AUTOSAR XML (schema 00044)
package /E40_Platform_System_SystemPackage/Components
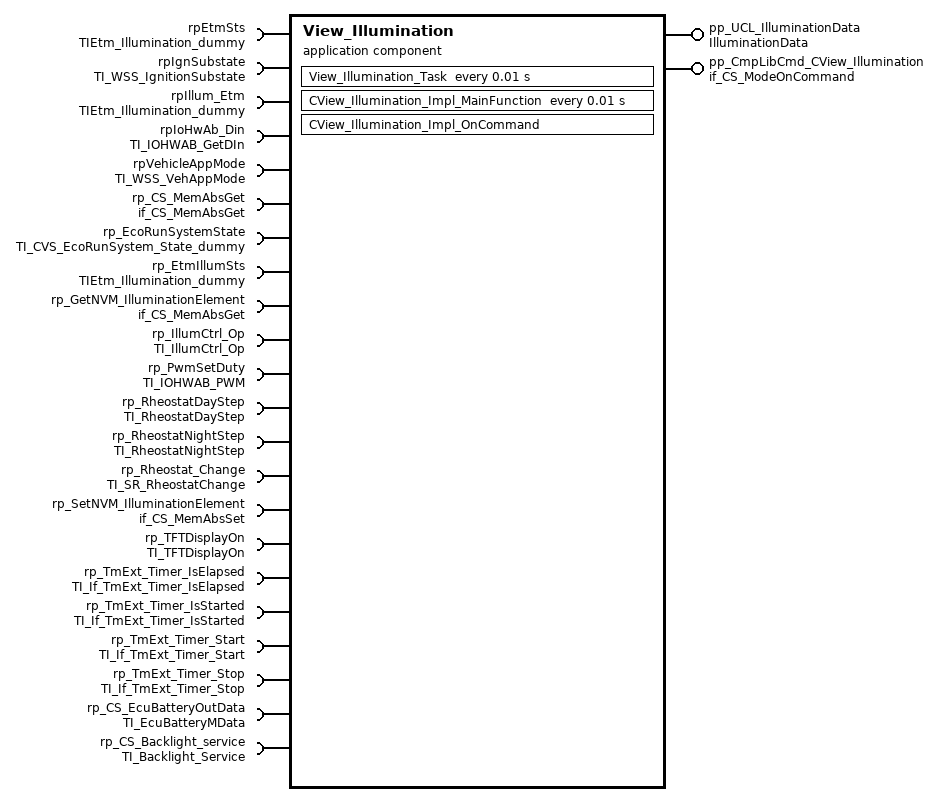
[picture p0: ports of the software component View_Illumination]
  application sw component type View_Illumination
    provide port pp_UCL_IlluminationData: nonqueued-sender-com-spec{data-element=IlluminationDataData, init-value=constant-reference=View_IlluminationIlluminationDataDataValue0}, provided-interface=IlluminationData
    20 x require port:
      rpEtmSts: nonqueued-receiver-com-spec{data-element=IllumStatus, init-value=constant-reference=View_IlluminationIllumStatusValue0}, required-interface=TIEtm_Illumination_dummy
      rpIgnSubstate: nonqueued-receiver-com-spec{data-element=IgnitionSubstate, init-value=constant-reference=View_IlluminationIgnitionSubstateValue0}, required-interface=TI_WSS_IgnitionSubstate
      rpIllum_Etm: nonqueued-receiver-com-spec{data-element=IllumStatus, init-value=constant-reference=View_IlluminationIllumStatusValue0}, required-interface=TIEtm_Illumination_dummy
      rpIoHwAb_Din: required-com-specs=[GetAsyncRawInput, GetInputGroup, GetProcessedInput, GetSyncRawInput], required-interface=TI_IOHWAB_GetDIn
      rpVehicleAppMode: nonqueued-receiver-com-spec{data-element=WSSCurrentVehicleState, init-value=constant-reference=View_IlluminationWSSCurrentVehicleStateValue0}, required-interface=TI_WSS_VehAppMode
      rp_CS_MemAbsGet: required-com-specs=[Get_BsConst_Audio_Element, Get_BsConst_Communication_Element, Get_BsConst_EngOffTimer_Element, Get_BsConst_FuelGauge_Element, Get_BsConst_OilGauge_Element, Get_BsConst_PowerGauge_Element, Get_BsConst_Power_Element, Get_BsConst_RealTimeClock_Element, Get_BsConst_ServiceReminder_Element, Get_BsConst_SpeedoGauge_Element, Get_BsConst_TachoGauge_Element, Get_BsConst_TempGauge_Element, Get_BsConst_TripComputer_Element, Get_BsConst_Warning_Element, Get_BsCys_Certicificate_Element, Get_BsDiag_Dtc_Element, Get_BsDiag_ErrorRecord_Element, Get_BsReten_Audio_Element, Get_BsReten_Communication_Element, Get_BsReten_Display_Element, Get_BsReten_Gauges_Element, Get_BsReten_Illumination_Element, Get_BsReten_Odometer_Element, Get_BsReten_Personalization_Element, Get_BsReten_Power_Element, Get_BsReten_RealTimeClock_Element, Get_BsReten_Tripcomputer_Element, Get_BsReten_Warning_Element, Get_BsRt_CusDlt_Element, Get_BsRt_FuelGauge_Element, Get_BsRt_Illumination_Element, Get_BsRt_Odometer_Element, Get_BsRt_OilGauge_Element, Get_BsRt_Personalization_Element, Get_BsRt_PowerGauge_Element, Get_BsRt_RealTimeClock_Element, Get_BsRt_SpeedoGauge_Element, Get_BsRt_TachoGauge_Element, Get_BsRt_TempGauge_Element, Get_BsRt_TripComputer_Element, Get_BsRt_Warning_Element, Get_BsShare_EcuPartNumber_Element, Get_BsShare_SwUpdFotaFinPrint_Element, Get_BsShare_SwUpdFotaMode_Element, Get_BsShare_SwUpdFotaStatus_Element, Get_BsShare_SwUpdFotadecrypt_Element, Get_BsShare_SwUpdReflash_Element, Get_BsShare_VehicleConfig_Element, Get_BsShare_VisMeet_Element, Get_RefCys_Certicificate1_Element, Get_RefCys_Certicificate_Element, Get_BsShare_VisMeet_EOLEntry_Element, Get_BsShare_AssemblyManufacturingDate, Get_BsShare_AssemblyPlantNumber, Get_BsShare_HWModification, Get_BsShare_PCBSerialNumber, Get_BsShare_ProductSerialNumber, Get_BsShare_SMTManufacturingDate, Get_BsShare_SMTPlantNumber, Get_BsShare_VisteonPCBPartNumber, Get_BsShare_VisteonPartNumber, Get_BsConst_BsConst_Illumination_ReservedByte, Get_BsConst_BsConst_Illumination_ReservedByte_SafeCopy1, Get_BsConst_BsConst_Illumination_ReservedByte_SafeCopy2, Get_BsConst_Compensation_Line_Shift_b, Get_BsConst_Compensation_Line_Shift_b_SafeCopy1, Get_BsConst_Compensation_Line_Shift_b_SafeCopy2, Get_BsConst_Compensation_Line_Slope_m, Get_BsConst_Compensation_Line_Slope_m_SafeCopy1, Get_BsConst_Compensation_Line_Slope_m_SafeCopy2, Get_BsConst_Derating_Backlight_Disable, Get_BsConst_Derating_Backlight_Disable_SafeCopy1, Get_BsConst_Derating_Backlight_Disable_SafeCopy2, Get_BsConst_Display_Illum_Max_Level, Get_BsConst_Display_Illum_Max_Level_SafeCopy1, Get_BsConst_Display_Illum_Max_Level_SafeCopy2, Get_BsConst_Lookup_Curve_HotSpot_Coef_X, Get_BsConst_Lookup_Curve_HotSpot_Coef_X_SafeCopy1, Get_BsConst_Lookup_Curve_HotSpot_Coef_X_SafeCopy2, Get_BsConst_Lookup_Curve_HotSpot_Coef_Y, Get_BsConst_Lookup_Curve_HotSpot_Coef_Y_SafeCopy1, Get_BsConst_Lookup_Curve_HotSpot_Coef_Y_SafeCopy2, Get_BsConst_PCB_Temperature_Sensor_Conv, Get_BsConst_PCB_Temperature_Sensor_Conv_SafeCopy1, Get_BsConst_PCB_Temperature_Sensor_Conv_SafeCopy2, Get_BsConst_PWM_boost_bypass_duty, Get_BsConst_PWM_boost_bypass_duty_SafeCopy1, Get_BsConst_PWM_boost_bypass_duty_SafeCopy2, Get_BsConst_Temp_Threshold_Hysteresis_Derating, Get_BsConst_Temp_Threshold_Hysteresis_Derating_SafeCopy1, Get_BsConst_Temp_Threshold_Hysteresis_Derating_SafeCopy2, Get_BsConst_Temperature_Sensor_Conv, Get_BsConst_Temperature_Sensor_Conv_SafeCopy1, Get_BsConst_Temperature_Sensor_Conv_SafeCopy2], required-interface=if_CS_MemAbsGet
      rp_EcoRunSystemState: nonqueued-receiver-com-spec{data-element=EcoRunSystem_Flag, init-value=constant-reference=View_IlluminationEcoRunSystem_FlagValue0}, required-interface=TI_CVS_EcoRunSystem_State_dummy
      rp_EtmIllumSts: nonqueued-receiver-com-spec{data-element=IllumStatus, init-value=constant-reference=View_IlluminationIllumStatusValue0}, required-interface=TIEtm_Illumination_dummy
      rp_GetNVM_IlluminationElement: required-com-specs=[Get_BsConst_Audio_Element, Get_BsConst_Communication_Element, Get_BsConst_EngOffTimer_Element, Get_BsConst_FuelGauge_Element, Get_BsConst_OilGauge_Element, Get_BsConst_PowerGauge_Element, Get_BsConst_Power_Element, Get_BsConst_RealTimeClock_Element, Get_BsConst_ServiceReminder_Element, Get_BsConst_SpeedoGauge_Element, Get_BsConst_TachoGauge_Element, Get_BsConst_TempGauge_Element, Get_BsConst_TripComputer_Element, Get_BsConst_Warning_Element, Get_BsCys_Certicificate_Element, Get_BsDiag_Dtc_Element, Get_BsDiag_ErrorRecord_Element, Get_BsReten_Audio_Element, Get_BsReten_Communication_Element, Get_BsReten_Display_Element, Get_BsReten_Gauges_Element, Get_BsReten_Illumination_Element, Get_BsReten_Odometer_Element, Get_BsReten_Personalization_Element, Get_BsReten_Power_Element, Get_BsReten_RealTimeClock_Element, Get_BsReten_Tripcomputer_Element, Get_BsReten_Warning_Element, Get_BsRt_CusDlt_Element, Get_BsRt_FuelGauge_Element, Get_BsRt_Illumination_Element, Get_BsRt_Odometer_Element, Get_BsRt_OilGauge_Element, Get_BsRt_Personalization_Element, Get_BsRt_PowerGauge_Element, Get_BsRt_RealTimeClock_Element, Get_BsRt_SpeedoGauge_Element, Get_BsRt_TachoGauge_Element, Get_BsRt_TempGauge_Element, Get_BsRt_TripComputer_Element, Get_BsRt_Warning_Element, Get_BsShare_EcuPartNumber_Element, Get_BsShare_SwUpdFotaFinPrint_Element, Get_BsShare_SwUpdFotaMode_Element, Get_BsShare_SwUpdFotaStatus_Element, Get_BsShare_SwUpdFotadecrypt_Element, Get_BsShare_SwUpdReflash_Element, Get_BsShare_VehicleConfig_Element, Get_BsShare_VisMeet_Element, Get_RefCys_Certicificate1_Element, Get_RefCys_Certicificate_Element, Get_BsShare_VisMeet_EOLEntry_Element, Get_BsShare_AssemblyManufacturingDate, Get_BsShare_AssemblyPlantNumber, Get_BsShare_HWModification, Get_BsShare_PCBSerialNumber, Get_BsShare_ProductSerialNumber, Get_BsShare_SMTManufacturingDate, Get_BsShare_SMTPlantNumber, Get_BsShare_VisteonPCBPartNumber, Get_BsShare_VisteonPartNumber, Get_BsConst_BsConst_Illumination_ReservedByte, Get_BsConst_BsConst_Illumination_ReservedByte_SafeCopy1, Get_BsConst_BsConst_Illumination_ReservedByte_SafeCopy2, Get_BsConst_Compensation_Line_Shift_b, Get_BsConst_Compensation_Line_Shift_b_SafeCopy1, Get_BsConst_Compensation_Line_Shift_b_SafeCopy2, Get_BsConst_Compensation_Line_Slope_m, Get_BsConst_Compensation_Line_Slope_m_SafeCopy1, Get_BsConst_Compensation_Line_Slope_m_SafeCopy2, Get_BsConst_Derating_Backlight_Disable, Get_BsConst_Derating_Backlight_Disable_SafeCopy1, Get_BsConst_Derating_Backlight_Disable_SafeCopy2, Get_BsConst_Display_Illum_Max_Level, Get_BsConst_Display_Illum_Max_Level_SafeCopy1, Get_BsConst_Display_Illum_Max_Level_SafeCopy2, Get_BsConst_Lookup_Curve_HotSpot_Coef_X, Get_BsConst_Lookup_Curve_HotSpot_Coef_X_SafeCopy1, Get_BsConst_Lookup_Curve_HotSpot_Coef_X_SafeCopy2, Get_BsConst_Lookup_Curve_HotSpot_Coef_Y, Get_BsConst_Lookup_Curve_HotSpot_Coef_Y_SafeCopy1, Get_BsConst_Lookup_Curve_HotSpot_Coef_Y_SafeCopy2, Get_BsConst_PCB_Temperature_Sensor_Conv, Get_BsConst_PCB_Temperature_Sensor_Conv_SafeCopy1, Get_BsConst_PCB_Temperature_Sensor_Conv_SafeCopy2, Get_BsConst_PWM_boost_bypass_duty, Get_BsConst_PWM_boost_bypass_duty_SafeCopy1, Get_BsConst_PWM_boost_bypass_duty_SafeCopy2, Get_BsConst_Temp_Threshold_Hysteresis_Derating, Get_BsConst_Temp_Threshold_Hysteresis_Derating_SafeCopy1, Get_BsConst_Temp_Threshold_Hysteresis_Derating_SafeCopy2, Get_BsConst_Temperature_Sensor_Conv, Get_BsConst_Temperature_Sensor_Conv_SafeCopy1, Get_BsConst_Temperature_Sensor_Conv_SafeCopy2], required-interface=if_CS_MemAbsGet
      rp_IllumCtrl_Op: nonqueued-receiver-com-spec{data-element=IllumCtrl_Op_Data, init-value=constant-reference=View_IlluminationIllumCtrl_Op_DataValue0}, required-interface=TI_IllumCtrl_Op
      rp_PwmSetDuty: required-com-specs=[PwmSetDuty, PwmSetDutyAndPeriod, PwmSetIdeal], required-interface=TI_IOHWAB_PWM
      rp_RheostatDayStep: nonqueued-receiver-com-spec{data-element=RheostatDayStep, init-value=constant-reference=View_IlluminationRheostatDayStepValue0}, required-interface=TI_RheostatDayStep
      rp_RheostatNightStep: nonqueued-receiver-com-spec{data-element=RheostatNightStep, init-value=constant-reference=View_IlluminationRheostatNightStepValue0}, required-interface=TI_RheostatNightStep
      rp_Rheostat_Change: nonqueued-receiver-com-spec{data-element=RheoUpdateVal, init-value=constant-reference=View_IlluminationRheoUpdateValValue0}, required-interface=TI_SR_RheostatChange
      rp_SetNVM_IlluminationElement: required-com-specs=[Set_BsConst_Audio_Element, Set_BsConst_Communication_Element, Set_BsConst_EngOffTimer_Element, Set_BsConst_FuelGauge_Element, Set_BsConst_OilGauge_Element, Set_BsConst_PowerGauge_Element, Set_BsConst_Power_Element, Set_BsConst_RealTimeClock_Element, Set_BsConst_ServiceReminder_Element, Set_BsConst_SpeedoGauge_Element, Set_BsConst_TachoGauge_Element, Set_BsConst_TempGauge_Element, Set_BsConst_TripComputer_Element, Set_BsConst_Warning_Element, Set_BsCys_Certicificate_Element, Set_BsDiag_Dtc_Element, Set_BsDiag_ErrorRecord_Element, Set_BsReten_Audio_Element, Set_BsReten_Communication_Element, Set_BsReten_Display_Element, Set_BsReten_Gauges_Element, Set_BsReten_Illumination_Element, Set_BsReten_Odometer_Element, Set_BsReten_Personalization_Element, Set_BsReten_Power_Element, Set_BsReten_RealTimeClock_Element, Set_BsReten_Tripcomputer_Element, Set_BsReten_Warning_Element, Set_BsRt_CusDlt_Element, Set_BsRt_FuelGauge_Element, Set_BsRt_Illumination_Element, Set_BsRt_Odometer_Element, Set_BsRt_OilGauge_Element, Set_BsRt_Personalization_Element, Set_BsRt_PowerGauge_Element, Set_BsRt_RealTimeClock_Element, Set_BsRt_SpeedoGauge_Element, Set_BsRt_TachoGauge_Element, Set_BsRt_TempGauge_Element, Set_BsRt_TripComputer_Element, Set_BsRt_Warning_Element, Set_BsShare_EcuPartNumber_Element, Set_BsShare_SwUpdFotaFinPrint_Element, Set_BsShare_SwUpdFotaMode_Element, Set_BsShare_SwUpdFotaStatus_Element, Set_BsShare_SwUpdFotadecrypt_Element, Set_BsShare_SwUpdReflash_Element, Set_BsShare_VehicleConfig_Element, Set_BsShare_VisMeet_Element, Set_RefCys_Certicificate1_Element, Set_RefCys_Certicificate_Element, Set_BsShare_VisMeet_EOLEntry_Element, Set_BsShare_AssemblyManufacturingDate, Set_BsShare_AssemblyPlantNumber, Set_BsShare_HWModification, Set_BsShare_PCBSerialNumber, Set_BsShare_ProductSerialNumber, Set_BsShare_SMTManufacturingDate, Set_BsShare_SMTPlantNumber, Set_BsShare_VisteonPCBPartNumber, Set_BsShare_VisteonPartNumber, Set_BsConst_BsConst_Illumination_ReservedByte, Set_BsConst_BsConst_Illumination_ReservedByte_SafeCopy1, Set_BsConst_BsConst_Illumination_ReservedByte_SafeCopy2, Set_BsConst_Compensation_Line_Shift_b, Set_BsConst_Compensation_Line_Shift_b_SafeCopy1, Set_BsConst_Compensation_Line_Shift_b_SafeCopy2, Set_BsConst_Compensation_Line_Slope_m, Set_BsConst_Compensation_Line_Slope_m_SafeCopy1, Set_BsConst_Compensation_Line_Slope_m_SafeCopy2, Set_BsConst_Derating_Backlight_Disable, Set_BsConst_Derating_Backlight_Disable_SafeCopy1, Set_BsConst_Derating_Backlight_Disable_SafeCopy2, Set_BsConst_Display_Illum_Max_Level, Set_BsConst_Display_Illum_Max_Level_SafeCopy1, Set_BsConst_Display_Illum_Max_Level_SafeCopy2, Set_BsConst_Lookup_Curve_HotSpot_Coef_X, Set_BsConst_Lookup_Curve_HotSpot_Coef_X_SafeCopy1, Set_BsConst_Lookup_Curve_HotSpot_Coef_X_SafeCopy2, Set_BsConst_Lookup_Curve_HotSpot_Coef_Y, Set_BsConst_Lookup_Curve_HotSpot_Coef_Y_SafeCopy1, Set_BsConst_Lookup_Curve_HotSpot_Coef_Y_SafeCopy2, Set_BsConst_PCB_Temperature_Sensor_Conv, Set_BsConst_PCB_Temperature_Sensor_Conv_SafeCopy1, Set_BsConst_PCB_Temperature_Sensor_Conv_SafeCopy2, Set_BsConst_PWM_boost_bypass_duty, Set_BsConst_PWM_boost_bypass_duty_SafeCopy1, Set_BsConst_PWM_boost_bypass_duty_SafeCopy2, Set_BsConst_Temp_Threshold_Hysteresis_Derating, Set_BsConst_Temp_Threshold_Hysteresis_Derating_SafeCopy1, Set_BsConst_Temp_Threshold_Hysteresis_Derating_SafeCopy2, Set_BsConst_Temperature_Sensor_Conv, Set_BsConst_Temperature_Sensor_Conv_SafeCopy1, Set_BsConst_Temperature_Sensor_Conv_SafeCopy2], required-interface=if_CS_MemAbsSet
      rp_TFTDisplayOn: nonqueued-receiver-com-spec{data-element=TFTDisplayOn, init-value=constant-reference=View_IlluminationTFTDisplayOnValue0}, required-interface=TI_TFTDisplayOn
      rp_TmExt_Timer_IsElapsed: client-com-spec=Timer_IsElapsed, required-interface=TI_If_TmExt_Timer_IsElapsed
      rp_TmExt_Timer_IsStarted: client-com-spec=Timer_IsStarted, required-interface=TI_If_TmExt_Timer_IsStarted
      rp_TmExt_Timer_Start: client-com-spec=Timer_Start, required-interface=TI_If_TmExt_Timer_Start
      rp_TmExt_Timer_Stop: client-com-spec=Timer_Stop, required-interface=TI_If_TmExt_Timer_Stop
    provide port pp_CmpLibCmd_CView_Illumination: server-com-spec{operation=Impl_OnCommand, queue-length=1}, provided-interface=if_CS_ModeOnCommand
    require port rp_CS_EcuBatteryOutData: required-com-specs=[EcuBatteryM_GetChannelStatus, EcuBatteryM_GetDIOStatus], required-interface=TI_EcuBatteryMData
    require port rp_CS_Backlight_service: required-com-specs=[GetBrightnessValue, GetThermalValue, SetBrightnessValue], required-interface=TI_Backlight_Service
    behavior IB_View_Illumination
      timing event TEView_Illumination_Task: start-on-event=View_Illumination_Task, period=0.01
      timing event TECView_Illumination_Impl_MainFunction: start-on-event=CView_Illumination_Impl_MainFunction, period=0.01
      operation invoked event OIE_pp_CmpLibCmd_CView_Illumination_CView_Illumination_Impl_OnCommandTrigByImpl_OnCommand: start-on-event=CView_Illumination_Impl_OnCommand, operation=pp_CmpLibCmd_CView_Illumination.Impl_OnCommand
      port-api-options:
        enable-take-address=false, indirect-api=false, port=pp_UCL_IlluminationData
        enable-take-address=false, indirect-api=false, port=rpEtmSts
        enable-take-address=false, indirect-api=false, port=rpIgnSubstate
        enable-take-address=false, indirect-api=false, port=rpIllum_Etm
        enable-take-address=false, indirect-api=false, port=rpIoHwAb_Din
        enable-take-address=false, indirect-api=false, port=rpVehicleAppMode
        enable-take-address=false, indirect-api=false, port=rp_CS_MemAbsGet
        enable-take-address=false, indirect-api=false, port=rp_EcoRunSystemState
        enable-take-address=false, indirect-api=false, port=rp_EtmIllumSts
        enable-take-address=false, indirect-api=false, port=rp_GetNVM_IlluminationElement
        enable-take-address=false, indirect-api=false, port=rp_IllumCtrl_Op
        enable-take-address=false, indirect-api=false, port=rp_PwmSetDuty
        enable-take-address=false, indirect-api=false, port=rp_RheostatDayStep
        enable-take-address=false, indirect-api=false, port=rp_RheostatNightStep
        enable-take-address=false, indirect-api=false, port=rp_Rheostat_Change
        enable-take-address=false, indirect-api=false, port=rp_SetNVM_IlluminationElement
        enable-take-address=false, indirect-api=false, port=rp_TFTDisplayOn
        enable-take-address=false, indirect-api=false, port=rp_TmExt_Timer_IsElapsed
        enable-take-address=false, indirect-api=false, port=rp_TmExt_Timer_IsStarted
        enable-take-address=false, indirect-api=false, port=rp_TmExt_Timer_Start
        enable-take-address=false, indirect-api=false, port=rp_TmExt_Timer_Stop
        enable-take-address=false, indirect-api=false, port=pp_CmpLibCmd_CView_Illumination
        enable-take-address=false, indirect-api=false, port=rp_CS_EcuBatteryOutData
        enable-take-address=false, indirect-api=false, port=rp_CS_Backlight_service
      runnable View_Illumination_Task: can-be-invoked-concurrently=true
        data-receive-point-by-arguments:
          11 x access:
            DRA_rpEtmSts_IllumStatus: accessed-variable=rpEtmSts.IllumStatus
            DRA_rpIgnSubstate_IgnitionSubstate: accessed-variable=rpIgnSubstate.IgnitionSubstate
            DRA_rpIllum_Etm_IllumStatus: accessed-variable=rpIllum_Etm.IllumStatus
            DRA_rpVehicleAppMode_WSSCurrentVehicleState: accessed-variable=rpVehicleAppMode.WSSCurrentVehicleState
            DRA_rp_EcoRunSystemState_EcoRunSystem_Flag: accessed-variable=rp_EcoRunSystemState.EcoRunSystem_Flag
            DRA_rp_EtmIllumSts_IllumStatus: accessed-variable=rp_EtmIllumSts.IllumStatus
            DRA_rp_IllumCtrl_Op_IllumCtrl_Op_Data: accessed-variable=rp_IllumCtrl_Op.IllumCtrl_Op_Data
            DRA_rp_RheostatDayStep_RheostatDayStep: accessed-variable=rp_RheostatDayStep.RheostatDayStep
            DRA_rp_RheostatNightStep_RheostatNightStep: accessed-variable=rp_RheostatNightStep.RheostatNightStep
            DRA_rp_Rheostat_Change_RheoUpdateVal: accessed-variable=rp_Rheostat_Change.RheoUpdateVal
            DRA_rp_TFTDisplayOn_TFTDisplayOn: accessed-variable=rp_TFTDisplayOn.TFTDisplayOn
        data-send-points:
          access DWA_pp_UCL_IlluminationData_IlluminationDataData: accessed-variable=pp_UCL_IlluminationData.IlluminationDataData
        298 x sync call:
          OA_rpIoHwAb_Din_GetAsyncRawInput: operation=rpIoHwAb_Din.GetAsyncRawInput
          OA_rpIoHwAb_Din_GetProcessedInput: operation=rpIoHwAb_Din.GetProcessedInput
          OA_rpIoHwAb_Din_GetSyncRawInput: operation=rpIoHwAb_Din.GetSyncRawInput
          OA_rpIoHwAb_Din_GetInputGroup: operation=rpIoHwAb_Din.GetInputGroup
          OA_rp_CS_MemAbsGet_Get_BsShare_SwUpdReflash_Element: operation=rp_CS_MemAbsGet.Get_BsShare_SwUpdReflash_Element
          OA_rp_CS_MemAbsGet_Get_BsShare_SwUpdFotaMode_Element: operation=rp_CS_MemAbsGet.Get_BsShare_SwUpdFotaMode_Element
          OA_rp_CS_MemAbsGet_Get_BsShare_SwUpdFotaFinPrint_Element: operation=rp_CS_MemAbsGet.Get_BsShare_SwUpdFotaFinPrint_Element
          OA_rp_CS_MemAbsGet_Get_BsShare_SwUpdFotaStatus_Element: operation=rp_CS_MemAbsGet.Get_BsShare_SwUpdFotaStatus_Element
          OA_rp_CS_MemAbsGet_Get_BsShare_SwUpdFotadecrypt_Element: operation=rp_CS_MemAbsGet.Get_BsShare_SwUpdFotadecrypt_Element
          OA_rp_CS_MemAbsGet_Get_BsShare_EcuPartNumber_Element: operation=rp_CS_MemAbsGet.Get_BsShare_EcuPartNumber_Element
          OA_rp_CS_MemAbsGet_Get_BsShare_VisteonPartNumber: operation=rp_CS_MemAbsGet.Get_BsShare_VisteonPartNumber
          OA_rp_CS_MemAbsGet_Get_BsShare_VisteonPCBPartNumber: operation=rp_CS_MemAbsGet.Get_BsShare_VisteonPCBPartNumber
          OA_rp_CS_MemAbsGet_Get_BsShare_ProductSerialNumber: operation=rp_CS_MemAbsGet.Get_BsShare_ProductSerialNumber
          OA_rp_CS_MemAbsGet_Get_BsShare_PCBSerialNumber: operation=rp_CS_MemAbsGet.Get_BsShare_PCBSerialNumber
          OA_rp_CS_MemAbsGet_Get_BsShare_SMTManufacturingDate: operation=rp_CS_MemAbsGet.Get_BsShare_SMTManufacturingDate
          OA_rp_CS_MemAbsGet_Get_BsShare_AssemblyManufacturingDate: operation=rp_CS_MemAbsGet.Get_BsShare_AssemblyManufacturingDate
          OA_rp_CS_MemAbsGet_Get_BsShare_SMTPlantNumber: operation=rp_CS_MemAbsGet.Get_BsShare_SMTPlantNumber
          OA_rp_CS_MemAbsGet_Get_BsShare_AssemblyPlantNumber: operation=rp_CS_MemAbsGet.Get_BsShare_AssemblyPlantNumber
          OA_rp_CS_MemAbsGet_Get_BsShare_HWModification: operation=rp_CS_MemAbsGet.Get_BsShare_HWModification
          OA_rp_CS_MemAbsGet_Get_BsShare_VisMeet_Element: operation=rp_CS_MemAbsGet.Get_BsShare_VisMeet_Element
          OA_rp_CS_MemAbsGet_Get_BsShare_VisMeet_EOLEntry_Element: operation=rp_CS_MemAbsGet.Get_BsShare_VisMeet_EOLEntry_Element
          OA_rp_CS_MemAbsGet_Get_BsShare_VehicleConfig_Element: operation=rp_CS_MemAbsGet.Get_BsShare_VehicleConfig_Element
          OA_rp_CS_MemAbsGet_Get_BsConst_SpeedoGauge_Element: operation=rp_CS_MemAbsGet.Get_BsConst_SpeedoGauge_Element
          OA_rp_CS_MemAbsGet_Get_BsConst_TachoGauge_Element: operation=rp_CS_MemAbsGet.Get_BsConst_TachoGauge_Element
          OA_rp_CS_MemAbsGet_Get_BsConst_FuelGauge_Element: operation=rp_CS_MemAbsGet.Get_BsConst_FuelGauge_Element
          OA_rp_CS_MemAbsGet_Get_BsConst_TempGauge_Element: operation=rp_CS_MemAbsGet.Get_BsConst_TempGauge_Element
          OA_rp_CS_MemAbsGet_Get_BsConst_PowerGauge_Element: operation=rp_CS_MemAbsGet.Get_BsConst_PowerGauge_Element
          OA_rp_CS_MemAbsGet_Get_BsConst_OilGauge_Element: operation=rp_CS_MemAbsGet.Get_BsConst_OilGauge_Element
          OA_rp_CS_MemAbsGet_Get_BsConst_TripComputer_Element: operation=rp_CS_MemAbsGet.Get_BsConst_TripComputer_Element
          OA_rp_CS_MemAbsGet_Get_BsConst_Compensation_Line_Slope_m: operation=rp_CS_MemAbsGet.Get_BsConst_Compensation_Line_Slope_m
          OA_rp_CS_MemAbsGet_Get_BsConst_Compensation_Line_Shift_b: operation=rp_CS_MemAbsGet.Get_BsConst_Compensation_Line_Shift_b
          OA_rp_CS_MemAbsGet_Get_BsConst_Lookup_Curve_HotSpot_Coef_X: operation=rp_CS_MemAbsGet.Get_BsConst_Lookup_Curve_HotSpot_Coef_X
          OA_rp_CS_MemAbsGet_Get_BsConst_Lookup_Curve_HotSpot_Coef_Y: operation=rp_CS_MemAbsGet.Get_BsConst_Lookup_Curve_HotSpot_Coef_Y
          OA_rp_CS_MemAbsGet_Get_BsConst_Temp_Threshold_Hysteresis_Derating: operation=rp_CS_MemAbsGet.Get_BsConst_Temp_Threshold_Hysteresis_Derating
          OA_rp_CS_MemAbsGet_Get_BsConst_Derating_Backlight_Disable: operation=rp_CS_MemAbsGet.Get_BsConst_Derating_Backlight_Disable
          OA_rp_CS_MemAbsGet_Get_BsConst_Temperature_Sensor_Conv: operation=rp_CS_MemAbsGet.Get_BsConst_Temperature_Sensor_Conv
          OA_rp_CS_MemAbsGet_Get_BsConst_PCB_Temperature_Sensor_Conv: operation=rp_CS_MemAbsGet.Get_BsConst_PCB_Temperature_Sensor_Conv
          OA_rp_CS_MemAbsGet_Get_BsConst_Display_Illum_Max_Level: operation=rp_CS_MemAbsGet.Get_BsConst_Display_Illum_Max_Level
          OA_rp_CS_MemAbsGet_Get_BsConst_PWM_boost_bypass_duty: operation=rp_CS_MemAbsGet.Get_BsConst_PWM_boost_bypass_duty
          OA_rp_CS_MemAbsGet_Get_BsConst_BsConst_Illumination_ReservedByte: operation=rp_CS_MemAbsGet.Get_BsConst_BsConst_Illumination_ReservedByte
          OA_rp_CS_MemAbsGet_Get_BsConst_Compensation_Line_Slope_m_SafeCopy1: operation=rp_CS_MemAbsGet.Get_BsConst_Compensation_Line_Slope_m_SafeCopy1
          OA_rp_CS_MemAbsGet_Get_BsConst_Compensation_Line_Shift_b_SafeCopy1: operation=rp_CS_MemAbsGet.Get_BsConst_Compensation_Line_Shift_b_SafeCopy1
          OA_rp_CS_MemAbsGet_Get_BsConst_Lookup_Curve_HotSpot_Coef_X_SafeCopy1: operation=rp_CS_MemAbsGet.Get_BsConst_Lookup_Curve_HotSpot_Coef_X_SafeCopy1
          OA_rp_CS_MemAbsGet_Get_BsConst_Lookup_Curve_HotSpot_Coef_Y_SafeCopy1: operation=rp_CS_MemAbsGet.Get_BsConst_Lookup_Curve_HotSpot_Coef_Y_SafeCopy1
          OA_rp_CS_MemAbsGet_Get_BsConst_Temp_Threshold_Hysteresis_Derating_SafeCopy1: operation=rp_CS_MemAbsGet.Get_BsConst_Temp_Threshold_Hysteresis_Derating_SafeCopy1
          OA_rp_CS_MemAbsGet_Get_BsConst_Derating_Backlight_Disable_SafeCopy1: operation=rp_CS_MemAbsGet.Get_BsConst_Derating_Backlight_Disable_SafeCopy1
          OA_rp_CS_MemAbsGet_Get_BsConst_Temperature_Sensor_Conv_SafeCopy1: operation=rp_CS_MemAbsGet.Get_BsConst_Temperature_Sensor_Conv_SafeCopy1
          OA_rp_CS_MemAbsGet_Get_BsConst_PCB_Temperature_Sensor_Conv_SafeCopy1: operation=rp_CS_MemAbsGet.Get_BsConst_PCB_Temperature_Sensor_Conv_SafeCopy1
          OA_rp_CS_MemAbsGet_Get_BsConst_Display_Illum_Max_Level_SafeCopy1: operation=rp_CS_MemAbsGet.Get_BsConst_Display_Illum_Max_Level_SafeCopy1
          OA_rp_CS_MemAbsGet_Get_BsConst_PWM_boost_bypass_duty_SafeCopy1: operation=rp_CS_MemAbsGet.Get_BsConst_PWM_boost_bypass_duty_SafeCopy1
          OA_rp_CS_MemAbsGet_Get_BsConst_BsConst_Illumination_ReservedByte_SafeCopy1: operation=rp_CS_MemAbsGet.Get_BsConst_BsConst_Illumination_ReservedByte_SafeCopy1
          OA_rp_CS_MemAbsGet_Get_BsConst_Compensation_Line_Slope_m_SafeCopy2: operation=rp_CS_MemAbsGet.Get_BsConst_Compensation_Line_Slope_m_SafeCopy2
          OA_rp_CS_MemAbsGet_Get_BsConst_Compensation_Line_Shift_b_SafeCopy2: operation=rp_CS_MemAbsGet.Get_BsConst_Compensation_Line_Shift_b_SafeCopy2
          OA_rp_CS_MemAbsGet_Get_BsConst_Lookup_Curve_HotSpot_Coef_X_SafeCopy2: operation=rp_CS_MemAbsGet.Get_BsConst_Lookup_Curve_HotSpot_Coef_X_SafeCopy2
          OA_rp_CS_MemAbsGet_Get_BsConst_Lookup_Curve_HotSpot_Coef_Y_SafeCopy2: operation=rp_CS_MemAbsGet.Get_BsConst_Lookup_Curve_HotSpot_Coef_Y_SafeCopy2
          OA_rp_CS_MemAbsGet_Get_BsConst_Temp_Threshold_Hysteresis_Derating_SafeCopy2: operation=rp_CS_MemAbsGet.Get_BsConst_Temp_Threshold_Hysteresis_Derating_SafeCopy2
          OA_rp_CS_MemAbsGet_Get_BsConst_Derating_Backlight_Disable_SafeCopy2: operation=rp_CS_MemAbsGet.Get_BsConst_Derating_Backlight_Disable_SafeCopy2
          OA_rp_CS_MemAbsGet_Get_BsConst_Temperature_Sensor_Conv_SafeCopy2: operation=rp_CS_MemAbsGet.Get_BsConst_Temperature_Sensor_Conv_SafeCopy2
          OA_rp_CS_MemAbsGet_Get_BsConst_PCB_Temperature_Sensor_Conv_SafeCopy2: operation=rp_CS_MemAbsGet.Get_BsConst_PCB_Temperature_Sensor_Conv_SafeCopy2
          OA_rp_CS_MemAbsGet_Get_BsConst_Display_Illum_Max_Level_SafeCopy2: operation=rp_CS_MemAbsGet.Get_BsConst_Display_Illum_Max_Level_SafeCopy2
          OA_rp_CS_MemAbsGet_Get_BsConst_PWM_boost_bypass_duty_SafeCopy2: operation=rp_CS_MemAbsGet.Get_BsConst_PWM_boost_bypass_duty_SafeCopy2
          OA_rp_CS_MemAbsGet_Get_BsConst_BsConst_Illumination_ReservedByte_SafeCopy2: operation=rp_CS_MemAbsGet.Get_BsConst_BsConst_Illumination_ReservedByte_SafeCopy2
          OA_rp_CS_MemAbsGet_Get_BsConst_Audio_Element: operation=rp_CS_MemAbsGet.Get_BsConst_Audio_Element
          OA_rp_CS_MemAbsGet_Get_BsConst_Warning_Element: operation=rp_CS_MemAbsGet.Get_BsConst_Warning_Element
          OA_rp_CS_MemAbsGet_Get_BsConst_RealTimeClock_Element: operation=rp_CS_MemAbsGet.Get_BsConst_RealTimeClock_Element
          OA_rp_CS_MemAbsGet_Get_BsConst_Communication_Element: operation=rp_CS_MemAbsGet.Get_BsConst_Communication_Element
          OA_rp_CS_MemAbsGet_Get_BsConst_Power_Element: operation=rp_CS_MemAbsGet.Get_BsConst_Power_Element
          OA_rp_CS_MemAbsGet_Get_BsConst_ServiceReminder_Element: operation=rp_CS_MemAbsGet.Get_BsConst_ServiceReminder_Element
          OA_rp_CS_MemAbsGet_Get_BsConst_EngOffTimer_Element: operation=rp_CS_MemAbsGet.Get_BsConst_EngOffTimer_Element
          OA_rp_CS_MemAbsGet_Get_BsCys_Certicificate_Element: operation=rp_CS_MemAbsGet.Get_BsCys_Certicificate_Element
          OA_rp_CS_MemAbsGet_Get_RefCys_Certicificate_Element: operation=rp_CS_MemAbsGet.Get_RefCys_Certicificate_Element
          OA_rp_CS_MemAbsGet_Get_RefCys_Certicificate1_Element: operation=rp_CS_MemAbsGet.Get_RefCys_Certicificate1_Element
          OA_rp_CS_MemAbsGet_Get_BsRt_Odometer_Element: operation=rp_CS_MemAbsGet.Get_BsRt_Odometer_Element
          OA_rp_CS_MemAbsGet_Get_BsRt_SpeedoGauge_Element: operation=rp_CS_MemAbsGet.Get_BsRt_SpeedoGauge_Element
          OA_rp_CS_MemAbsGet_Get_BsRt_TachoGauge_Element: operation=rp_CS_MemAbsGet.Get_BsRt_TachoGauge_Element
          OA_rp_CS_MemAbsGet_Get_BsRt_FuelGauge_Element: operation=rp_CS_MemAbsGet.Get_BsRt_FuelGauge_Element
          OA_rp_CS_MemAbsGet_Get_BsRt_TempGauge_Element: operation=rp_CS_MemAbsGet.Get_BsRt_TempGauge_Element
          OA_rp_CS_MemAbsGet_Get_BsRt_PowerGauge_Element: operation=rp_CS_MemAbsGet.Get_BsRt_PowerGauge_Element
          OA_rp_CS_MemAbsGet_Get_BsRt_OilGauge_Element: operation=rp_CS_MemAbsGet.Get_BsRt_OilGauge_Element
          OA_rp_CS_MemAbsGet_Get_BsRt_TripComputer_Element: operation=rp_CS_MemAbsGet.Get_BsRt_TripComputer_Element
          OA_rp_CS_MemAbsGet_Get_BsRt_Warning_Element: operation=rp_CS_MemAbsGet.Get_BsRt_Warning_Element
          OA_rp_CS_MemAbsGet_Get_BsRt_RealTimeClock_Element: operation=rp_CS_MemAbsGet.Get_BsRt_RealTimeClock_Element
          OA_rp_CS_MemAbsGet_Get_BsRt_Personalization_Element: operation=rp_CS_MemAbsGet.Get_BsRt_Personalization_Element
          OA_rp_CS_MemAbsGet_Get_BsRt_Illumination_Element: operation=rp_CS_MemAbsGet.Get_BsRt_Illumination_Element
          OA_rp_CS_MemAbsGet_Get_BsRt_CusDlt_Element: operation=rp_CS_MemAbsGet.Get_BsRt_CusDlt_Element
          OA_rp_CS_MemAbsGet_Get_BsReten_Odometer_Element: operation=rp_CS_MemAbsGet.Get_BsReten_Odometer_Element
          OA_rp_CS_MemAbsGet_Get_BsReten_Gauges_Element: operation=rp_CS_MemAbsGet.Get_BsReten_Gauges_Element
          OA_rp_CS_MemAbsGet_Get_BsReten_Tripcomputer_Element: operation=rp_CS_MemAbsGet.Get_BsReten_Tripcomputer_Element
          OA_rp_CS_MemAbsGet_Get_BsReten_Illumination_Element: operation=rp_CS_MemAbsGet.Get_BsReten_Illumination_Element
          OA_rp_CS_MemAbsGet_Get_BsReten_Audio_Element: operation=rp_CS_MemAbsGet.Get_BsReten_Audio_Element
          OA_rp_CS_MemAbsGet_Get_BsReten_Warning_Element: operation=rp_CS_MemAbsGet.Get_BsReten_Warning_Element
          OA_rp_CS_MemAbsGet_Get_BsReten_RealTimeClock_Element: operation=rp_CS_MemAbsGet.Get_BsReten_RealTimeClock_Element
          OA_rp_CS_MemAbsGet_Get_BsReten_Communication_Element: operation=rp_CS_MemAbsGet.Get_BsReten_Communication_Element
          OA_rp_CS_MemAbsGet_Get_BsReten_Personalization_Element: operation=rp_CS_MemAbsGet.Get_BsReten_Personalization_Element
          OA_rp_CS_MemAbsGet_Get_BsReten_Power_Element: operation=rp_CS_MemAbsGet.Get_BsReten_Power_Element
          OA_rp_CS_MemAbsGet_Get_BsReten_Display_Element: operation=rp_CS_MemAbsGet.Get_BsReten_Display_Element
          OA_rp_CS_MemAbsGet_Get_BsDiag_ErrorRecord_Element: operation=rp_CS_MemAbsGet.Get_BsDiag_ErrorRecord_Element
          OA_rp_CS_MemAbsGet_Get_BsDiag_Dtc_Element: operation=rp_CS_MemAbsGet.Get_BsDiag_Dtc_Element
          OA_rp_GetNVM_IlluminationElement_Get_BsShare_SwUpdReflash_Element: operation=rp_GetNVM_IlluminationElement.Get_BsShare_SwUpdReflash_Element
          OA_rp_GetNVM_IlluminationElement_Get_BsShare_SwUpdFotaMode_Element: operation=rp_GetNVM_IlluminationElement.Get_BsShare_SwUpdFotaMode_Element
          OA_rp_GetNVM_IlluminationElement_Get_BsShare_SwUpdFotaFinPrint_Element: operation=rp_GetNVM_IlluminationElement.Get_BsShare_SwUpdFotaFinPrint_Element
          OA_rp_GetNVM_IlluminationElement_Get_BsShare_SwUpdFotaStatus_Element: operation=rp_GetNVM_IlluminationElement.Get_BsShare_SwUpdFotaStatus_Element
          OA_rp_GetNVM_IlluminationElement_Get_BsShare_SwUpdFotadecrypt_Element: operation=rp_GetNVM_IlluminationElement.Get_BsShare_SwUpdFotadecrypt_Element
          OA_rp_GetNVM_IlluminationElement_Get_BsShare_EcuPartNumber_Element: operation=rp_GetNVM_IlluminationElement.Get_BsShare_EcuPartNumber_Element
          OA_rp_GetNVM_IlluminationElement_Get_BsShare_VisteonPartNumber: operation=rp_GetNVM_IlluminationElement.Get_BsShare_VisteonPartNumber
          OA_rp_GetNVM_IlluminationElement_Get_BsShare_VisteonPCBPartNumber: operation=rp_GetNVM_IlluminationElement.Get_BsShare_VisteonPCBPartNumber
          OA_rp_GetNVM_IlluminationElement_Get_BsShare_ProductSerialNumber: operation=rp_GetNVM_IlluminationElement.Get_BsShare_ProductSerialNumber
          OA_rp_GetNVM_IlluminationElement_Get_BsShare_PCBSerialNumber: operation=rp_GetNVM_IlluminationElement.Get_BsShare_PCBSerialNumber
          OA_rp_GetNVM_IlluminationElement_Get_BsShare_SMTManufacturingDate: operation=rp_GetNVM_IlluminationElement.Get_BsShare_SMTManufacturingDate
          OA_rp_GetNVM_IlluminationElement_Get_BsShare_AssemblyManufacturingDate: operation=rp_GetNVM_IlluminationElement.Get_BsShare_AssemblyManufacturingDate
          OA_rp_GetNVM_IlluminationElement_Get_BsShare_SMTPlantNumber: operation=rp_GetNVM_IlluminationElement.Get_BsShare_SMTPlantNumber
          OA_rp_GetNVM_IlluminationElement_Get_BsShare_AssemblyPlantNumber: operation=rp_GetNVM_IlluminationElement.Get_BsShare_AssemblyPlantNumber
          OA_rp_GetNVM_IlluminationElement_Get_BsShare_HWModification: operation=rp_GetNVM_IlluminationElement.Get_BsShare_HWModification
          OA_rp_GetNVM_IlluminationElement_Get_BsShare_VisMeet_Element: operation=rp_GetNVM_IlluminationElement.Get_BsShare_VisMeet_Element
          OA_rp_GetNVM_IlluminationElement_Get_BsShare_VisMeet_EOLEntry_Element: operation=rp_GetNVM_IlluminationElement.Get_BsShare_VisMeet_EOLEntry_Element
          OA_rp_GetNVM_IlluminationElement_Get_BsShare_VehicleConfig_Element: operation=rp_GetNVM_IlluminationElement.Get_BsShare_VehicleConfig_Element
          OA_rp_GetNVM_IlluminationElement_Get_BsConst_SpeedoGauge_Element: operation=rp_GetNVM_IlluminationElement.Get_BsConst_SpeedoGauge_Element
          OA_rp_GetNVM_IlluminationElement_Get_BsConst_TachoGauge_Element: operation=rp_GetNVM_IlluminationElement.Get_BsConst_TachoGauge_Element
          OA_rp_GetNVM_IlluminationElement_Get_BsConst_FuelGauge_Element: operation=rp_GetNVM_IlluminationElement.Get_BsConst_FuelGauge_Element
          OA_rp_GetNVM_IlluminationElement_Get_BsConst_TempGauge_Element: operation=rp_GetNVM_IlluminationElement.Get_BsConst_TempGauge_Element
          OA_rp_GetNVM_IlluminationElement_Get_BsConst_PowerGauge_Element: operation=rp_GetNVM_IlluminationElement.Get_BsConst_PowerGauge_Element
          OA_rp_GetNVM_IlluminationElement_Get_BsConst_OilGauge_Element: operation=rp_GetNVM_IlluminationElement.Get_BsConst_OilGauge_Element
          OA_rp_GetNVM_IlluminationElement_Get_BsConst_TripComputer_Element: operation=rp_GetNVM_IlluminationElement.Get_BsConst_TripComputer_Element
          OA_rp_GetNVM_IlluminationElement_Get_BsConst_Compensation_Line_Slope_m: operation=rp_GetNVM_IlluminationElement.Get_BsConst_Compensation_Line_Slope_m
          OA_rp_GetNVM_IlluminationElement_Get_BsConst_Compensation_Line_Shift_b: operation=rp_GetNVM_IlluminationElement.Get_BsConst_Compensation_Line_Shift_b
          OA_rp_GetNVM_IlluminationElement_Get_BsConst_Lookup_Curve_HotSpot_Coef_X: operation=rp_GetNVM_IlluminationElement.Get_BsConst_Lookup_Curve_HotSpot_Coef_X
          OA_rp_GetNVM_IlluminationElement_Get_BsConst_Lookup_Curve_HotSpot_Coef_Y: operation=rp_GetNVM_IlluminationElement.Get_BsConst_Lookup_Curve_HotSpot_Coef_Y
          OA_rp_GetNVM_IlluminationElement_Get_BsConst_Temp_Threshold_Hysteresis_Derating: operation=rp_GetNVM_IlluminationElement.Get_BsConst_Temp_Threshold_Hysteresis_Derating
          OA_rp_GetNVM_IlluminationElement_Get_BsConst_Derating_Backlight_Disable: operation=rp_GetNVM_IlluminationElement.Get_BsConst_Derating_Backlight_Disable
          OA_rp_GetNVM_IlluminationElement_Get_BsConst_Temperature_Sensor_Conv: operation=rp_GetNVM_IlluminationElement.Get_BsConst_Temperature_Sensor_Conv
          OA_rp_GetNVM_IlluminationElement_Get_BsConst_PCB_Temperature_Sensor_Conv: operation=rp_GetNVM_IlluminationElement.Get_BsConst_PCB_Temperature_Sensor_Conv
          OA_rp_GetNVM_IlluminationElement_Get_BsConst_Display_Illum_Max_Level: operation=rp_GetNVM_IlluminationElement.Get_BsConst_Display_Illum_Max_Level
          OA_rp_GetNVM_IlluminationElement_Get_BsConst_PWM_boost_bypass_duty: operation=rp_GetNVM_IlluminationElement.Get_BsConst_PWM_boost_bypass_duty
          OA_rp_GetNVM_IlluminationElement_Get_BsConst_BsConst_Illumination_ReservedByte: operation=rp_GetNVM_IlluminationElement.Get_BsConst_BsConst_Illumination_ReservedByte
          OA_rp_GetNVM_IlluminationElement_Get_BsConst_Compensation_Line_Slope_m_SafeCopy1: operation=rp_GetNVM_IlluminationElement.Get_BsConst_Compensation_Line_Slope_m_SafeCopy1
          OA_rp_GetNVM_IlluminationElement_Get_BsConst_Compensation_Line_Shift_b_SafeCopy1: operation=rp_GetNVM_IlluminationElement.Get_BsConst_Compensation_Line_Shift_b_SafeCopy1
          OA_rp_GetNVM_IlluminationElement_Get_BsConst_Lookup_Curve_HotSpot_Coef_X_SafeCopy1: operation=rp_GetNVM_IlluminationElement.Get_BsConst_Lookup_Curve_HotSpot_Coef_X_SafeCopy1
          OA_rp_GetNVM_IlluminationElement_Get_BsConst_Lookup_Curve_HotSpot_Coef_Y_SafeCopy1: operation=rp_GetNVM_IlluminationElement.Get_BsConst_Lookup_Curve_HotSpot_Coef_Y_SafeCopy1
          OA_rp_GetNVM_IlluminationElement_Get_BsConst_Temp_Threshold_Hysteresis_Derating_SafeCopy1: operation=rp_GetNVM_IlluminationElement.Get_BsConst_Temp_Threshold_Hysteresis_Derating_SafeCopy1
          OA_rp_GetNVM_IlluminationElement_Get_BsConst_Derating_Backlight_Disable_SafeCopy1: operation=rp_GetNVM_IlluminationElement.Get_BsConst_Derating_Backlight_Disable_SafeCopy1
          OA_rp_GetNVM_IlluminationElement_Get_BsConst_Temperature_Sensor_Conv_SafeCopy1: operation=rp_GetNVM_IlluminationElement.Get_BsConst_Temperature_Sensor_Conv_SafeCopy1
          OA_rp_GetNVM_IlluminationElement_Get_BsConst_PCB_Temperature_Sensor_Conv_SafeCopy1: operation=rp_GetNVM_IlluminationElement.Get_BsConst_PCB_Temperature_Sensor_Conv_SafeCopy1
          OA_rp_GetNVM_IlluminationElement_Get_BsConst_Display_Illum_Max_Level_SafeCopy1: operation=rp_GetNVM_IlluminationElement.Get_BsConst_Display_Illum_Max_Level_SafeCopy1
          OA_rp_GetNVM_IlluminationElement_Get_BsConst_PWM_boost_bypass_duty_SafeCopy1: operation=rp_GetNVM_IlluminationElement.Get_BsConst_PWM_boost_bypass_duty_SafeCopy1
          OA_rp_GetNVM_IlluminationElement_Get_BsConst_BsConst_Illumination_ReservedByte_SafeCopy1: operation=rp_GetNVM_IlluminationElement.Get_BsConst_BsConst_Illumination_ReservedByte_SafeCopy1
          OA_rp_GetNVM_IlluminationElement_Get_BsConst_Compensation_Line_Slope_m_SafeCopy2: operation=rp_GetNVM_IlluminationElement.Get_BsConst_Compensation_Line_Slope_m_SafeCopy2
          OA_rp_GetNVM_IlluminationElement_Get_BsConst_Compensation_Line_Shift_b_SafeCopy2: operation=rp_GetNVM_IlluminationElement.Get_BsConst_Compensation_Line_Shift_b_SafeCopy2
          OA_rp_GetNVM_IlluminationElement_Get_BsConst_Lookup_Curve_HotSpot_Coef_X_SafeCopy2: operation=rp_GetNVM_IlluminationElement.Get_BsConst_Lookup_Curve_HotSpot_Coef_X_SafeCopy2
          OA_rp_GetNVM_IlluminationElement_Get_BsConst_Lookup_Curve_HotSpot_Coef_Y_SafeCopy2: operation=rp_GetNVM_IlluminationElement.Get_BsConst_Lookup_Curve_HotSpot_Coef_Y_SafeCopy2
          OA_rp_GetNVM_IlluminationElement_Get_BsConst_Temp_Threshold_Hysteresis_Derating_SafeCopy2: operation=rp_GetNVM_IlluminationElement.Get_BsConst_Temp_Threshold_Hysteresis_Derating_SafeCopy2
          OA_rp_GetNVM_IlluminationElement_Get_BsConst_Derating_Backlight_Disable_SafeCopy2: operation=rp_GetNVM_IlluminationElement.Get_BsConst_Derating_Backlight_Disable_SafeCopy2
          OA_rp_GetNVM_IlluminationElement_Get_BsConst_Temperature_Sensor_Conv_SafeCopy2: operation=rp_GetNVM_IlluminationElement.Get_BsConst_Temperature_Sensor_Conv_SafeCopy2
          OA_rp_GetNVM_IlluminationElement_Get_BsConst_PCB_Temperature_Sensor_Conv_SafeCopy2: operation=rp_GetNVM_IlluminationElement.Get_BsConst_PCB_Temperature_Sensor_Conv_SafeCopy2
          OA_rp_GetNVM_IlluminationElement_Get_BsConst_Display_Illum_Max_Level_SafeCopy2: operation=rp_GetNVM_IlluminationElement.Get_BsConst_Display_Illum_Max_Level_SafeCopy2
          OA_rp_GetNVM_IlluminationElement_Get_BsConst_PWM_boost_bypass_duty_SafeCopy2: operation=rp_GetNVM_IlluminationElement.Get_BsConst_PWM_boost_bypass_duty_SafeCopy2
          OA_rp_GetNVM_IlluminationElement_Get_BsConst_BsConst_Illumination_ReservedByte_SafeCopy2: operation=rp_GetNVM_IlluminationElement.Get_BsConst_BsConst_Illumination_ReservedByte_SafeCopy2
          OA_rp_GetNVM_IlluminationElement_Get_BsConst_Audio_Element: operation=rp_GetNVM_IlluminationElement.Get_BsConst_Audio_Element
          OA_rp_GetNVM_IlluminationElement_Get_BsConst_Warning_Element: operation=rp_GetNVM_IlluminationElement.Get_BsConst_Warning_Element
          OA_rp_GetNVM_IlluminationElement_Get_BsConst_RealTimeClock_Element: operation=rp_GetNVM_IlluminationElement.Get_BsConst_RealTimeClock_Element
          OA_rp_GetNVM_IlluminationElement_Get_BsConst_Communication_Element: operation=rp_GetNVM_IlluminationElement.Get_BsConst_Communication_Element
          OA_rp_GetNVM_IlluminationElement_Get_BsConst_Power_Element: operation=rp_GetNVM_IlluminationElement.Get_BsConst_Power_Element
          OA_rp_GetNVM_IlluminationElement_Get_BsConst_ServiceReminder_Element: operation=rp_GetNVM_IlluminationElement.Get_BsConst_ServiceReminder_Element
          OA_rp_GetNVM_IlluminationElement_Get_BsConst_EngOffTimer_Element: operation=rp_GetNVM_IlluminationElement.Get_BsConst_EngOffTimer_Element
          OA_rp_GetNVM_IlluminationElement_Get_BsCys_Certicificate_Element: operation=rp_GetNVM_IlluminationElement.Get_BsCys_Certicificate_Element
          OA_rp_GetNVM_IlluminationElement_Get_RefCys_Certicificate_Element: operation=rp_GetNVM_IlluminationElement.Get_RefCys_Certicificate_Element
          OA_rp_GetNVM_IlluminationElement_Get_RefCys_Certicificate1_Element: operation=rp_GetNVM_IlluminationElement.Get_RefCys_Certicificate1_Element
          OA_rp_GetNVM_IlluminationElement_Get_BsRt_Odometer_Element: operation=rp_GetNVM_IlluminationElement.Get_BsRt_Odometer_Element
          OA_rp_GetNVM_IlluminationElement_Get_BsRt_SpeedoGauge_Element: operation=rp_GetNVM_IlluminationElement.Get_BsRt_SpeedoGauge_Element
          OA_rp_GetNVM_IlluminationElement_Get_BsRt_TachoGauge_Element: operation=rp_GetNVM_IlluminationElement.Get_BsRt_TachoGauge_Element
          OA_rp_GetNVM_IlluminationElement_Get_BsRt_FuelGauge_Element: operation=rp_GetNVM_IlluminationElement.Get_BsRt_FuelGauge_Element
          OA_rp_GetNVM_IlluminationElement_Get_BsRt_TempGauge_Element: operation=rp_GetNVM_IlluminationElement.Get_BsRt_TempGauge_Element
          OA_rp_GetNVM_IlluminationElement_Get_BsRt_PowerGauge_Element: operation=rp_GetNVM_IlluminationElement.Get_BsRt_PowerGauge_Element
          OA_rp_GetNVM_IlluminationElement_Get_BsRt_OilGauge_Element: operation=rp_GetNVM_IlluminationElement.Get_BsRt_OilGauge_Element
          OA_rp_GetNVM_IlluminationElement_Get_BsRt_TripComputer_Element: operation=rp_GetNVM_IlluminationElement.Get_BsRt_TripComputer_Element
          OA_rp_GetNVM_IlluminationElement_Get_BsRt_Warning_Element: operation=rp_GetNVM_IlluminationElement.Get_BsRt_Warning_Element
          OA_rp_GetNVM_IlluminationElement_Get_BsRt_RealTimeClock_Element: operation=rp_GetNVM_IlluminationElement.Get_BsRt_RealTimeClock_Element
          OA_rp_GetNVM_IlluminationElement_Get_BsRt_Personalization_Element: operation=rp_GetNVM_IlluminationElement.Get_BsRt_Personalization_Element
          OA_rp_GetNVM_IlluminationElement_Get_BsRt_Illumination_Element: operation=rp_GetNVM_IlluminationElement.Get_BsRt_Illumination_Element
          OA_rp_GetNVM_IlluminationElement_Get_BsRt_CusDlt_Element: operation=rp_GetNVM_IlluminationElement.Get_BsRt_CusDlt_Element
          OA_rp_GetNVM_IlluminationElement_Get_BsReten_Odometer_Element: operation=rp_GetNVM_IlluminationElement.Get_BsReten_Odometer_Element
          OA_rp_GetNVM_IlluminationElement_Get_BsReten_Gauges_Element: operation=rp_GetNVM_IlluminationElement.Get_BsReten_Gauges_Element
          OA_rp_GetNVM_IlluminationElement_Get_BsReten_Tripcomputer_Element: operation=rp_GetNVM_IlluminationElement.Get_BsReten_Tripcomputer_Element
          OA_rp_GetNVM_IlluminationElement_Get_BsReten_Illumination_Element: operation=rp_GetNVM_IlluminationElement.Get_BsReten_Illumination_Element
          OA_rp_GetNVM_IlluminationElement_Get_BsReten_Audio_Element: operation=rp_GetNVM_IlluminationElement.Get_BsReten_Audio_Element
          OA_rp_GetNVM_IlluminationElement_Get_BsReten_Warning_Element: operation=rp_GetNVM_IlluminationElement.Get_BsReten_Warning_Element
          OA_rp_GetNVM_IlluminationElement_Get_BsReten_RealTimeClock_Element: operation=rp_GetNVM_IlluminationElement.Get_BsReten_RealTimeClock_Element
          OA_rp_GetNVM_IlluminationElement_Get_BsReten_Communication_Element: operation=rp_GetNVM_IlluminationElement.Get_BsReten_Communication_Element
          OA_rp_GetNVM_IlluminationElement_Get_BsReten_Personalization_Element: operation=rp_GetNVM_IlluminationElement.Get_BsReten_Personalization_Element
          OA_rp_GetNVM_IlluminationElement_Get_BsReten_Power_Element: operation=rp_GetNVM_IlluminationElement.Get_BsReten_Power_Element
          OA_rp_GetNVM_IlluminationElement_Get_BsReten_Display_Element: operation=rp_GetNVM_IlluminationElement.Get_BsReten_Display_Element
          OA_rp_GetNVM_IlluminationElement_Get_BsDiag_ErrorRecord_Element: operation=rp_GetNVM_IlluminationElement.Get_BsDiag_ErrorRecord_Element
          OA_rp_GetNVM_IlluminationElement_Get_BsDiag_Dtc_Element: operation=rp_GetNVM_IlluminationElement.Get_BsDiag_Dtc_Element
          OA_rp_PwmSetDuty_PwmSetDuty: operation=rp_PwmSetDuty.PwmSetDuty
          OA_rp_PwmSetDuty_PwmSetDutyAndPeriod: operation=rp_PwmSetDuty.PwmSetDutyAndPeriod
          OA_rp_PwmSetDuty_PwmSetIdeal: operation=rp_PwmSetDuty.PwmSetIdeal
          OA_rp_SetNVM_IlluminationElement_Set_BsShare_SwUpdReflash_Element: operation=rp_SetNVM_IlluminationElement.Set_BsShare_SwUpdReflash_Element
          OA_rp_SetNVM_IlluminationElement_Set_BsShare_SwUpdFotaMode_Element: operation=rp_SetNVM_IlluminationElement.Set_BsShare_SwUpdFotaMode_Element
          OA_rp_SetNVM_IlluminationElement_Set_BsShare_SwUpdFotaFinPrint_Element: operation=rp_SetNVM_IlluminationElement.Set_BsShare_SwUpdFotaFinPrint_Element
          OA_rp_SetNVM_IlluminationElement_Set_BsShare_SwUpdFotaStatus_Element: operation=rp_SetNVM_IlluminationElement.Set_BsShare_SwUpdFotaStatus_Element
          OA_rp_SetNVM_IlluminationElement_Set_BsShare_SwUpdFotadecrypt_Element: operation=rp_SetNVM_IlluminationElement.Set_BsShare_SwUpdFotadecrypt_Element
          OA_rp_SetNVM_IlluminationElement_Set_BsShare_EcuPartNumber_Element: operation=rp_SetNVM_IlluminationElement.Set_BsShare_EcuPartNumber_Element
          OA_rp_SetNVM_IlluminationElement_Set_BsShare_VisteonPartNumber: operation=rp_SetNVM_IlluminationElement.Set_BsShare_VisteonPartNumber
          OA_rp_SetNVM_IlluminationElement_Set_BsShare_VisteonPCBPartNumber: operation=rp_SetNVM_IlluminationElement.Set_BsShare_VisteonPCBPartNumber
          OA_rp_SetNVM_IlluminationElement_Set_BsShare_ProductSerialNumber: operation=rp_SetNVM_IlluminationElement.Set_BsShare_ProductSerialNumber
          OA_rp_SetNVM_IlluminationElement_Set_BsShare_PCBSerialNumber: operation=rp_SetNVM_IlluminationElement.Set_BsShare_PCBSerialNumber
          OA_rp_SetNVM_IlluminationElement_Set_BsShare_SMTManufacturingDate: operation=rp_SetNVM_IlluminationElement.Set_BsShare_SMTManufacturingDate
          OA_rp_SetNVM_IlluminationElement_Set_BsShare_AssemblyManufacturingDate: operation=rp_SetNVM_IlluminationElement.Set_BsShare_AssemblyManufacturingDate
          OA_rp_SetNVM_IlluminationElement_Set_BsShare_SMTPlantNumber: operation=rp_SetNVM_IlluminationElement.Set_BsShare_SMTPlantNumber
          OA_rp_SetNVM_IlluminationElement_Set_BsShare_AssemblyPlantNumber: operation=rp_SetNVM_IlluminationElement.Set_BsShare_AssemblyPlantNumber
          OA_rp_SetNVM_IlluminationElement_Set_BsShare_HWModification: operation=rp_SetNVM_IlluminationElement.Set_BsShare_HWModification
          OA_rp_SetNVM_IlluminationElement_Set_BsShare_VisMeet_Element: operation=rp_SetNVM_IlluminationElement.Set_BsShare_VisMeet_Element
          OA_rp_SetNVM_IlluminationElement_Set_BsShare_VisMeet_EOLEntry_Element: operation=rp_SetNVM_IlluminationElement.Set_BsShare_VisMeet_EOLEntry_Element
          OA_rp_SetNVM_IlluminationElement_Set_BsShare_VehicleConfig_Element: operation=rp_SetNVM_IlluminationElement.Set_BsShare_VehicleConfig_Element
          OA_rp_SetNVM_IlluminationElement_Set_BsConst_SpeedoGauge_Element: operation=rp_SetNVM_IlluminationElement.Set_BsConst_SpeedoGauge_Element
          OA_rp_SetNVM_IlluminationElement_Set_BsConst_TachoGauge_Element: operation=rp_SetNVM_IlluminationElement.Set_BsConst_TachoGauge_Element
          OA_rp_SetNVM_IlluminationElement_Set_BsConst_FuelGauge_Element: operation=rp_SetNVM_IlluminationElement.Set_BsConst_FuelGauge_Element
          OA_rp_SetNVM_IlluminationElement_Set_BsConst_TempGauge_Element: operation=rp_SetNVM_IlluminationElement.Set_BsConst_TempGauge_Element
          OA_rp_SetNVM_IlluminationElement_Set_BsConst_PowerGauge_Element: operation=rp_SetNVM_IlluminationElement.Set_BsConst_PowerGauge_Element
          OA_rp_SetNVM_IlluminationElement_Set_BsConst_OilGauge_Element: operation=rp_SetNVM_IlluminationElement.Set_BsConst_OilGauge_Element
          OA_rp_SetNVM_IlluminationElement_Set_BsConst_TripComputer_Element: operation=rp_SetNVM_IlluminationElement.Set_BsConst_TripComputer_Element
          OA_rp_SetNVM_IlluminationElement_Set_BsConst_Compensation_Line_Slope_m: operation=rp_SetNVM_IlluminationElement.Set_BsConst_Compensation_Line_Slope_m
          OA_rp_SetNVM_IlluminationElement_Set_BsConst_Compensation_Line_Shift_b: operation=rp_SetNVM_IlluminationElement.Set_BsConst_Compensation_Line_Shift_b
          OA_rp_SetNVM_IlluminationElement_Set_BsConst_Lookup_Curve_HotSpot_Coef_X: operation=rp_SetNVM_IlluminationElement.Set_BsConst_Lookup_Curve_HotSpot_Coef_X
          OA_rp_SetNVM_IlluminationElement_Set_BsConst_Lookup_Curve_HotSpot_Coef_Y: operation=rp_SetNVM_IlluminationElement.Set_BsConst_Lookup_Curve_HotSpot_Coef_Y
          OA_rp_SetNVM_IlluminationElement_Set_BsConst_Temp_Threshold_Hysteresis_Derating: operation=rp_SetNVM_IlluminationElement.Set_BsConst_Temp_Threshold_Hysteresis_Derating
          OA_rp_SetNVM_IlluminationElement_Set_BsConst_Derating_Backlight_Disable: operation=rp_SetNVM_IlluminationElement.Set_BsConst_Derating_Backlight_Disable
          OA_rp_SetNVM_IlluminationElement_Set_BsConst_Temperature_Sensor_Conv: operation=rp_SetNVM_IlluminationElement.Set_BsConst_Temperature_Sensor_Conv
          OA_rp_SetNVM_IlluminationElement_Set_BsConst_PCB_Temperature_Sensor_Conv: operation=rp_SetNVM_IlluminationElement.Set_BsConst_PCB_Temperature_Sensor_Conv
          OA_rp_SetNVM_IlluminationElement_Set_BsConst_Display_Illum_Max_Level: operation=rp_SetNVM_IlluminationElement.Set_BsConst_Display_Illum_Max_Level
          OA_rp_SetNVM_IlluminationElement_Set_BsConst_PWM_boost_bypass_duty: operation=rp_SetNVM_IlluminationElement.Set_BsConst_PWM_boost_bypass_duty
          OA_rp_SetNVM_IlluminationElement_Set_BsConst_BsConst_Illumination_ReservedByte: operation=rp_SetNVM_IlluminationElement.Set_BsConst_BsConst_Illumination_ReservedByte
          OA_rp_SetNVM_IlluminationElement_Set_BsConst_Compensation_Line_Slope_m_SafeCopy1: operation=rp_SetNVM_IlluminationElement.Set_BsConst_Compensation_Line_Slope_m_SafeCopy1
          OA_rp_SetNVM_IlluminationElement_Set_BsConst_Compensation_Line_Shift_b_SafeCopy1: operation=rp_SetNVM_IlluminationElement.Set_BsConst_Compensation_Line_Shift_b_SafeCopy1
          OA_rp_SetNVM_IlluminationElement_Set_BsConst_Lookup_Curve_HotSpot_Coef_X_SafeCopy1: operation=rp_SetNVM_IlluminationElement.Set_BsConst_Lookup_Curve_HotSpot_Coef_X_SafeCopy1
          OA_rp_SetNVM_IlluminationElement_Set_BsConst_Lookup_Curve_HotSpot_Coef_Y_SafeCopy1: operation=rp_SetNVM_IlluminationElement.Set_BsConst_Lookup_Curve_HotSpot_Coef_Y_SafeCopy1
          OA_rp_SetNVM_IlluminationElement_Set_BsConst_Temp_Threshold_Hysteresis_Derating_SafeCopy1: operation=rp_SetNVM_IlluminationElement.Set_BsConst_Temp_Threshold_Hysteresis_Derating_SafeCopy1
          OA_rp_SetNVM_IlluminationElement_Set_BsConst_Derating_Backlight_Disable_SafeCopy1: operation=rp_SetNVM_IlluminationElement.Set_BsConst_Derating_Backlight_Disable_SafeCopy1
          OA_rp_SetNVM_IlluminationElement_Set_BsConst_Temperature_Sensor_Conv_SafeCopy1: operation=rp_SetNVM_IlluminationElement.Set_BsConst_Temperature_Sensor_Conv_SafeCopy1
          OA_rp_SetNVM_IlluminationElement_Set_BsConst_PCB_Temperature_Sensor_Conv_SafeCopy1: operation=rp_SetNVM_IlluminationElement.Set_BsConst_PCB_Temperature_Sensor_Conv_SafeCopy1
          OA_rp_SetNVM_IlluminationElement_Set_BsConst_Display_Illum_Max_Level_SafeCopy1: operation=rp_SetNVM_IlluminationElement.Set_BsConst_Display_Illum_Max_Level_SafeCopy1
          OA_rp_SetNVM_IlluminationElement_Set_BsConst_PWM_boost_bypass_duty_SafeCopy1: operation=rp_SetNVM_IlluminationElement.Set_BsConst_PWM_boost_bypass_duty_SafeCopy1
          OA_rp_SetNVM_IlluminationElement_Set_BsConst_BsConst_Illumination_ReservedByte_SafeCopy1: operation=rp_SetNVM_IlluminationElement.Set_BsConst_BsConst_Illumination_ReservedByte_SafeCopy1
          OA_rp_SetNVM_IlluminationElement_Set_BsConst_Compensation_Line_Slope_m_SafeCopy2: operation=rp_SetNVM_IlluminationElement.Set_BsConst_Compensation_Line_Slope_m_SafeCopy2
          OA_rp_SetNVM_IlluminationElement_Set_BsConst_Compensation_Line_Shift_b_SafeCopy2: operation=rp_SetNVM_IlluminationElement.Set_BsConst_Compensation_Line_Shift_b_SafeCopy2
          OA_rp_SetNVM_IlluminationElement_Set_BsConst_Lookup_Curve_HotSpot_Coef_X_SafeCopy2: operation=rp_SetNVM_IlluminationElement.Set_BsConst_Lookup_Curve_HotSpot_Coef_X_SafeCopy2
          OA_rp_SetNVM_IlluminationElement_Set_BsConst_Lookup_Curve_HotSpot_Coef_Y_SafeCopy2: operation=rp_SetNVM_IlluminationElement.Set_BsConst_Lookup_Curve_HotSpot_Coef_Y_SafeCopy2
          OA_rp_SetNVM_IlluminationElement_Set_BsConst_Temp_Threshold_Hysteresis_Derating_SafeCopy2: operation=rp_SetNVM_IlluminationElement.Set_BsConst_Temp_Threshold_Hysteresis_Derating_SafeCopy2
          OA_rp_SetNVM_IlluminationElement_Set_BsConst_Derating_Backlight_Disable_SafeCopy2: operation=rp_SetNVM_IlluminationElement.Set_BsConst_Derating_Backlight_Disable_SafeCopy2
          OA_rp_SetNVM_IlluminationElement_Set_BsConst_Temperature_Sensor_Conv_SafeCopy2: operation=rp_SetNVM_IlluminationElement.Set_BsConst_Temperature_Sensor_Conv_SafeCopy2
          OA_rp_SetNVM_IlluminationElement_Set_BsConst_PCB_Temperature_Sensor_Conv_SafeCopy2: operation=rp_SetNVM_IlluminationElement.Set_BsConst_PCB_Temperature_Sensor_Conv_SafeCopy2
          OA_rp_SetNVM_IlluminationElement_Set_BsConst_Display_Illum_Max_Level_SafeCopy2: operation=rp_SetNVM_IlluminationElement.Set_BsConst_Display_Illum_Max_Level_SafeCopy2
          OA_rp_SetNVM_IlluminationElement_Set_BsConst_PWM_boost_bypass_duty_SafeCopy2: operation=rp_SetNVM_IlluminationElement.Set_BsConst_PWM_boost_bypass_duty_SafeCopy2
          OA_rp_SetNVM_IlluminationElement_Set_BsConst_BsConst_Illumination_ReservedByte_SafeCopy2: operation=rp_SetNVM_IlluminationElement.Set_BsConst_BsConst_Illumination_ReservedByte_SafeCopy2
          OA_rp_SetNVM_IlluminationElement_Set_BsConst_Audio_Element: operation=rp_SetNVM_IlluminationElement.Set_BsConst_Audio_Element
          OA_rp_SetNVM_IlluminationElement_Set_BsConst_Warning_Element: operation=rp_SetNVM_IlluminationElement.Set_BsConst_Warning_Element
          OA_rp_SetNVM_IlluminationElement_Set_BsConst_RealTimeClock_Element: operation=rp_SetNVM_IlluminationElement.Set_BsConst_RealTimeClock_Element
          OA_rp_SetNVM_IlluminationElement_Set_BsConst_Communication_Element: operation=rp_SetNVM_IlluminationElement.Set_BsConst_Communication_Element
          OA_rp_SetNVM_IlluminationElement_Set_BsConst_Power_Element: operation=rp_SetNVM_IlluminationElement.Set_BsConst_Power_Element
          OA_rp_SetNVM_IlluminationElement_Set_BsConst_ServiceReminder_Element: operation=rp_SetNVM_IlluminationElement.Set_BsConst_ServiceReminder_Element
          OA_rp_SetNVM_IlluminationElement_Set_BsConst_EngOffTimer_Element: operation=rp_SetNVM_IlluminationElement.Set_BsConst_EngOffTimer_Element
          OA_rp_SetNVM_IlluminationElement_Set_BsCys_Certicificate_Element: operation=rp_SetNVM_IlluminationElement.Set_BsCys_Certicificate_Element
          OA_rp_SetNVM_IlluminationElement_Set_RefCys_Certicificate_Element: operation=rp_SetNVM_IlluminationElement.Set_RefCys_Certicificate_Element
          OA_rp_SetNVM_IlluminationElement_Set_RefCys_Certicificate1_Element: operation=rp_SetNVM_IlluminationElement.Set_RefCys_Certicificate1_Element
          OA_rp_SetNVM_IlluminationElement_Set_BsRt_Odometer_Element: operation=rp_SetNVM_IlluminationElement.Set_BsRt_Odometer_Element
          OA_rp_SetNVM_IlluminationElement_Set_BsRt_SpeedoGauge_Element: operation=rp_SetNVM_IlluminationElement.Set_BsRt_SpeedoGauge_Element
          OA_rp_SetNVM_IlluminationElement_Set_BsRt_TachoGauge_Element: operation=rp_SetNVM_IlluminationElement.Set_BsRt_TachoGauge_Element
          OA_rp_SetNVM_IlluminationElement_Set_BsRt_FuelGauge_Element: operation=rp_SetNVM_IlluminationElement.Set_BsRt_FuelGauge_Element
          OA_rp_SetNVM_IlluminationElement_Set_BsRt_TempGauge_Element: operation=rp_SetNVM_IlluminationElement.Set_BsRt_TempGauge_Element
          OA_rp_SetNVM_IlluminationElement_Set_BsRt_PowerGauge_Element: operation=rp_SetNVM_IlluminationElement.Set_BsRt_PowerGauge_Element
          OA_rp_SetNVM_IlluminationElement_Set_BsRt_OilGauge_Element: operation=rp_SetNVM_IlluminationElement.Set_BsRt_OilGauge_Element
          OA_rp_SetNVM_IlluminationElement_Set_BsRt_TripComputer_Element: operation=rp_SetNVM_IlluminationElement.Set_BsRt_TripComputer_Element
          OA_rp_SetNVM_IlluminationElement_Set_BsRt_Warning_Element: operation=rp_SetNVM_IlluminationElement.Set_BsRt_Warning_Element
          OA_rp_SetNVM_IlluminationElement_Set_BsRt_RealTimeClock_Element: operation=rp_SetNVM_IlluminationElement.Set_BsRt_RealTimeClock_Element
          OA_rp_SetNVM_IlluminationElement_Set_BsRt_Personalization_Element: operation=rp_SetNVM_IlluminationElement.Set_BsRt_Personalization_Element
          OA_rp_SetNVM_IlluminationElement_Set_BsRt_Illumination_Element: operation=rp_SetNVM_IlluminationElement.Set_BsRt_Illumination_Element
          OA_rp_SetNVM_IlluminationElement_Set_BsRt_CusDlt_Element: operation=rp_SetNVM_IlluminationElement.Set_BsRt_CusDlt_Element
          OA_rp_SetNVM_IlluminationElement_Set_BsReten_Odometer_Element: operation=rp_SetNVM_IlluminationElement.Set_BsReten_Odometer_Element
          OA_rp_SetNVM_IlluminationElement_Set_BsReten_Gauges_Element: operation=rp_SetNVM_IlluminationElement.Set_BsReten_Gauges_Element
          OA_rp_SetNVM_IlluminationElement_Set_BsReten_Tripcomputer_Element: operation=rp_SetNVM_IlluminationElement.Set_BsReten_Tripcomputer_Element
          OA_rp_SetNVM_IlluminationElement_Set_BsReten_Illumination_Element: operation=rp_SetNVM_IlluminationElement.Set_BsReten_Illumination_Element
          OA_rp_SetNVM_IlluminationElement_Set_BsReten_Audio_Element: operation=rp_SetNVM_IlluminationElement.Set_BsReten_Audio_Element
          OA_rp_SetNVM_IlluminationElement_Set_BsReten_Warning_Element: operation=rp_SetNVM_IlluminationElement.Set_BsReten_Warning_Element
          OA_rp_SetNVM_IlluminationElement_Set_BsReten_RealTimeClock_Element: operation=rp_SetNVM_IlluminationElement.Set_BsReten_RealTimeClock_Element
          OA_rp_SetNVM_IlluminationElement_Set_BsReten_Communication_Element: operation=rp_SetNVM_IlluminationElement.Set_BsReten_Communication_Element
          OA_rp_SetNVM_IlluminationElement_Set_BsReten_Personalization_Element: operation=rp_SetNVM_IlluminationElement.Set_BsReten_Personalization_Element
          OA_rp_SetNVM_IlluminationElement_Set_BsReten_Power_Element: operation=rp_SetNVM_IlluminationElement.Set_BsReten_Power_Element
          OA_rp_SetNVM_IlluminationElement_Set_BsReten_Display_Element: operation=rp_SetNVM_IlluminationElement.Set_BsReten_Display_Element
          OA_rp_SetNVM_IlluminationElement_Set_BsDiag_ErrorRecord_Element: operation=rp_SetNVM_IlluminationElement.Set_BsDiag_ErrorRecord_Element
          OA_rp_SetNVM_IlluminationElement_Set_BsDiag_Dtc_Element: operation=rp_SetNVM_IlluminationElement.Set_BsDiag_Dtc_Element
          OA_rp_TmExt_Timer_IsElapsed_Timer_IsElapsed: operation=rp_TmExt_Timer_IsElapsed.Timer_IsElapsed
          OA_rp_TmExt_Timer_IsStarted_Timer_IsStarted: operation=rp_TmExt_Timer_IsStarted.Timer_IsStarted
          OA_rp_TmExt_Timer_Start_Timer_Start: operation=rp_TmExt_Timer_Start.Timer_Start
          OA_rp_TmExt_Timer_Stop_Timer_Stop: operation=rp_TmExt_Timer_Stop.Timer_Stop
          OA_rp_CS_EcuBatteryOutData_EcuBatteryM_GetChannelStatus: operation=rp_CS_EcuBatteryOutData.EcuBatteryM_GetChannelStatus
          OA_rp_CS_EcuBatteryOutData_EcuBatteryM_GetDIOStatus: operation=rp_CS_EcuBatteryOutData.EcuBatteryM_GetDIOStatus
          OA_rp_CS_Backlight_service_SetBrightnessValue: operation=rp_CS_Backlight_service.SetBrightnessValue
          OA_rp_CS_Backlight_service_GetBrightnessValue: operation=rp_CS_Backlight_service.GetBrightnessValue
          OA_rp_CS_Backlight_service_GetThermalValue: operation=rp_CS_Backlight_service.GetThermalValue
      runnable CView_Illumination_Impl_MainFunction: can-be-invoked-concurrently=true
        data-receive-point-by-arguments:
          11 x access:
            DRA_rpEtmSts_IllumStatus: accessed-variable=rpEtmSts.IllumStatus
            DRA_rpIgnSubstate_IgnitionSubstate: accessed-variable=rpIgnSubstate.IgnitionSubstate
            DRA_rpIllum_Etm_IllumStatus: accessed-variable=rpIllum_Etm.IllumStatus
            DRA_rpVehicleAppMode_WSSCurrentVehicleState: accessed-variable=rpVehicleAppMode.WSSCurrentVehicleState
            DRA_rp_EcoRunSystemState_EcoRunSystem_Flag: accessed-variable=rp_EcoRunSystemState.EcoRunSystem_Flag
            DRA_rp_EtmIllumSts_IllumStatus: accessed-variable=rp_EtmIllumSts.IllumStatus
            DRA_rp_IllumCtrl_Op_IllumCtrl_Op_Data: accessed-variable=rp_IllumCtrl_Op.IllumCtrl_Op_Data
            DRA_rp_RheostatDayStep_RheostatDayStep: accessed-variable=rp_RheostatDayStep.RheostatDayStep
            DRA_rp_RheostatNightStep_RheostatNightStep: accessed-variable=rp_RheostatNightStep.RheostatNightStep
            DRA_rp_Rheostat_Change_RheoUpdateVal: accessed-variable=rp_Rheostat_Change.RheoUpdateVal
            DRA_rp_TFTDisplayOn_TFTDisplayOn: accessed-variable=rp_TFTDisplayOn.TFTDisplayOn
        data-send-points:
          access DWA_pp_UCL_IlluminationData_IlluminationDataData: accessed-variable=pp_UCL_IlluminationData.IlluminationDataData
        298 x sync call:
          OA_rpIoHwAb_Din_GetAsyncRawInput: operation=rpIoHwAb_Din.GetAsyncRawInput
          OA_rpIoHwAb_Din_GetProcessedInput: operation=rpIoHwAb_Din.GetProcessedInput
          OA_rpIoHwAb_Din_GetSyncRawInput: operation=rpIoHwAb_Din.GetSyncRawInput
          OA_rpIoHwAb_Din_GetInputGroup: operation=rpIoHwAb_Din.GetInputGroup
          OA_rp_CS_MemAbsGet_Get_BsShare_SwUpdReflash_Element: operation=rp_CS_MemAbsGet.Get_BsShare_SwUpdReflash_Element
          OA_rp_CS_MemAbsGet_Get_BsShare_SwUpdFotaMode_Element: operation=rp_CS_MemAbsGet.Get_BsShare_SwUpdFotaMode_Element
          OA_rp_CS_MemAbsGet_Get_BsShare_SwUpdFotaFinPrint_Element: operation=rp_CS_MemAbsGet.Get_BsShare_SwUpdFotaFinPrint_Element
          OA_rp_CS_MemAbsGet_Get_BsShare_SwUpdFotaStatus_Element: operation=rp_CS_MemAbsGet.Get_BsShare_SwUpdFotaStatus_Element
          OA_rp_CS_MemAbsGet_Get_BsShare_SwUpdFotadecrypt_Element: operation=rp_CS_MemAbsGet.Get_BsShare_SwUpdFotadecrypt_Element
          OA_rp_CS_MemAbsGet_Get_BsShare_EcuPartNumber_Element: operation=rp_CS_MemAbsGet.Get_BsShare_EcuPartNumber_Element
          OA_rp_CS_MemAbsGet_Get_BsShare_VisteonPartNumber: operation=rp_CS_MemAbsGet.Get_BsShare_VisteonPartNumber
          OA_rp_CS_MemAbsGet_Get_BsShare_VisteonPCBPartNumber: operation=rp_CS_MemAbsGet.Get_BsShare_VisteonPCBPartNumber
          OA_rp_CS_MemAbsGet_Get_BsShare_ProductSerialNumber: operation=rp_CS_MemAbsGet.Get_BsShare_ProductSerialNumber
          OA_rp_CS_MemAbsGet_Get_BsShare_PCBSerialNumber: operation=rp_CS_MemAbsGet.Get_BsShare_PCBSerialNumber
          OA_rp_CS_MemAbsGet_Get_BsShare_SMTManufacturingDate: operation=rp_CS_MemAbsGet.Get_BsShare_SMTManufacturingDate
          OA_rp_CS_MemAbsGet_Get_BsShare_AssemblyManufacturingDate: operation=rp_CS_MemAbsGet.Get_BsShare_AssemblyManufacturingDate
          OA_rp_CS_MemAbsGet_Get_BsShare_SMTPlantNumber: operation=rp_CS_MemAbsGet.Get_BsShare_SMTPlantNumber
          OA_rp_CS_MemAbsGet_Get_BsShare_AssemblyPlantNumber: operation=rp_CS_MemAbsGet.Get_BsShare_AssemblyPlantNumber
          OA_rp_CS_MemAbsGet_Get_BsShare_HWModification: operation=rp_CS_MemAbsGet.Get_BsShare_HWModification
          OA_rp_CS_MemAbsGet_Get_BsShare_VisMeet_Element: operation=rp_CS_MemAbsGet.Get_BsShare_VisMeet_Element
          OA_rp_CS_MemAbsGet_Get_BsShare_VisMeet_EOLEntry_Element: operation=rp_CS_MemAbsGet.Get_BsShare_VisMeet_EOLEntry_Element
          OA_rp_CS_MemAbsGet_Get_BsShare_VehicleConfig_Element: operation=rp_CS_MemAbsGet.Get_BsShare_VehicleConfig_Element
          OA_rp_CS_MemAbsGet_Get_BsConst_SpeedoGauge_Element: operation=rp_CS_MemAbsGet.Get_BsConst_SpeedoGauge_Element
          OA_rp_CS_MemAbsGet_Get_BsConst_TachoGauge_Element: operation=rp_CS_MemAbsGet.Get_BsConst_TachoGauge_Element
          OA_rp_CS_MemAbsGet_Get_BsConst_FuelGauge_Element: operation=rp_CS_MemAbsGet.Get_BsConst_FuelGauge_Element
          OA_rp_CS_MemAbsGet_Get_BsConst_TempGauge_Element: operation=rp_CS_MemAbsGet.Get_BsConst_TempGauge_Element
          OA_rp_CS_MemAbsGet_Get_BsConst_PowerGauge_Element: operation=rp_CS_MemAbsGet.Get_BsConst_PowerGauge_Element
          OA_rp_CS_MemAbsGet_Get_BsConst_OilGauge_Element: operation=rp_CS_MemAbsGet.Get_BsConst_OilGauge_Element
          OA_rp_CS_MemAbsGet_Get_BsConst_TripComputer_Element: operation=rp_CS_MemAbsGet.Get_BsConst_TripComputer_Element
          OA_rp_CS_MemAbsGet_Get_BsConst_Compensation_Line_Slope_m: operation=rp_CS_MemAbsGet.Get_BsConst_Compensation_Line_Slope_m
          OA_rp_CS_MemAbsGet_Get_BsConst_Compensation_Line_Shift_b: operation=rp_CS_MemAbsGet.Get_BsConst_Compensation_Line_Shift_b
          OA_rp_CS_MemAbsGet_Get_BsConst_Lookup_Curve_HotSpot_Coef_X: operation=rp_CS_MemAbsGet.Get_BsConst_Lookup_Curve_HotSpot_Coef_X
          OA_rp_CS_MemAbsGet_Get_BsConst_Lookup_Curve_HotSpot_Coef_Y: operation=rp_CS_MemAbsGet.Get_BsConst_Lookup_Curve_HotSpot_Coef_Y
          OA_rp_CS_MemAbsGet_Get_BsConst_Temp_Threshold_Hysteresis_Derating: operation=rp_CS_MemAbsGet.Get_BsConst_Temp_Threshold_Hysteresis_Derating
          OA_rp_CS_MemAbsGet_Get_BsConst_Derating_Backlight_Disable: operation=rp_CS_MemAbsGet.Get_BsConst_Derating_Backlight_Disable
          OA_rp_CS_MemAbsGet_Get_BsConst_Temperature_Sensor_Conv: operation=rp_CS_MemAbsGet.Get_BsConst_Temperature_Sensor_Conv
          OA_rp_CS_MemAbsGet_Get_BsConst_PCB_Temperature_Sensor_Conv: operation=rp_CS_MemAbsGet.Get_BsConst_PCB_Temperature_Sensor_Conv
          OA_rp_CS_MemAbsGet_Get_BsConst_Display_Illum_Max_Level: operation=rp_CS_MemAbsGet.Get_BsConst_Display_Illum_Max_Level
          OA_rp_CS_MemAbsGet_Get_BsConst_PWM_boost_bypass_duty: operation=rp_CS_MemAbsGet.Get_BsConst_PWM_boost_bypass_duty
          OA_rp_CS_MemAbsGet_Get_BsConst_BsConst_Illumination_ReservedByte: operation=rp_CS_MemAbsGet.Get_BsConst_BsConst_Illumination_ReservedByte
          OA_rp_CS_MemAbsGet_Get_BsConst_Compensation_Line_Slope_m_SafeCopy1: operation=rp_CS_MemAbsGet.Get_BsConst_Compensation_Line_Slope_m_SafeCopy1
          OA_rp_CS_MemAbsGet_Get_BsConst_Compensation_Line_Shift_b_SafeCopy1: operation=rp_CS_MemAbsGet.Get_BsConst_Compensation_Line_Shift_b_SafeCopy1
          OA_rp_CS_MemAbsGet_Get_BsConst_Lookup_Curve_HotSpot_Coef_X_SafeCopy1: operation=rp_CS_MemAbsGet.Get_BsConst_Lookup_Curve_HotSpot_Coef_X_SafeCopy1
          OA_rp_CS_MemAbsGet_Get_BsConst_Lookup_Curve_HotSpot_Coef_Y_SafeCopy1: operation=rp_CS_MemAbsGet.Get_BsConst_Lookup_Curve_HotSpot_Coef_Y_SafeCopy1
          OA_rp_CS_MemAbsGet_Get_BsConst_Temp_Threshold_Hysteresis_Derating_SafeCopy1: operation=rp_CS_MemAbsGet.Get_BsConst_Temp_Threshold_Hysteresis_Derating_SafeCopy1
          OA_rp_CS_MemAbsGet_Get_BsConst_Derating_Backlight_Disable_SafeCopy1: operation=rp_CS_MemAbsGet.Get_BsConst_Derating_Backlight_Disable_SafeCopy1
          OA_rp_CS_MemAbsGet_Get_BsConst_Temperature_Sensor_Conv_SafeCopy1: operation=rp_CS_MemAbsGet.Get_BsConst_Temperature_Sensor_Conv_SafeCopy1
          OA_rp_CS_MemAbsGet_Get_BsConst_PCB_Temperature_Sensor_Conv_SafeCopy1: operation=rp_CS_MemAbsGet.Get_BsConst_PCB_Temperature_Sensor_Conv_SafeCopy1
          OA_rp_CS_MemAbsGet_Get_BsConst_Display_Illum_Max_Level_SafeCopy1: operation=rp_CS_MemAbsGet.Get_BsConst_Display_Illum_Max_Level_SafeCopy1
          OA_rp_CS_MemAbsGet_Get_BsConst_PWM_boost_bypass_duty_SafeCopy1: operation=rp_CS_MemAbsGet.Get_BsConst_PWM_boost_bypass_duty_SafeCopy1
          OA_rp_CS_MemAbsGet_Get_BsConst_BsConst_Illumination_ReservedByte_SafeCopy1: operation=rp_CS_MemAbsGet.Get_BsConst_BsConst_Illumination_ReservedByte_SafeCopy1
          OA_rp_CS_MemAbsGet_Get_BsConst_Compensation_Line_Slope_m_SafeCopy2: operation=rp_CS_MemAbsGet.Get_BsConst_Compensation_Line_Slope_m_SafeCopy2
          OA_rp_CS_MemAbsGet_Get_BsConst_Compensation_Line_Shift_b_SafeCopy2: operation=rp_CS_MemAbsGet.Get_BsConst_Compensation_Line_Shift_b_SafeCopy2
          OA_rp_CS_MemAbsGet_Get_BsConst_Lookup_Curve_HotSpot_Coef_X_SafeCopy2: operation=rp_CS_MemAbsGet.Get_BsConst_Lookup_Curve_HotSpot_Coef_X_SafeCopy2
          OA_rp_CS_MemAbsGet_Get_BsConst_Lookup_Curve_HotSpot_Coef_Y_SafeCopy2: operation=rp_CS_MemAbsGet.Get_BsConst_Lookup_Curve_HotSpot_Coef_Y_SafeCopy2
          OA_rp_CS_MemAbsGet_Get_BsConst_Temp_Threshold_Hysteresis_Derating_SafeCopy2: operation=rp_CS_MemAbsGet.Get_BsConst_Temp_Threshold_Hysteresis_Derating_SafeCopy2
          OA_rp_CS_MemAbsGet_Get_BsConst_Derating_Backlight_Disable_SafeCopy2: operation=rp_CS_MemAbsGet.Get_BsConst_Derating_Backlight_Disable_SafeCopy2
          OA_rp_CS_MemAbsGet_Get_BsConst_Temperature_Sensor_Conv_SafeCopy2: operation=rp_CS_MemAbsGet.Get_BsConst_Temperature_Sensor_Conv_SafeCopy2
          OA_rp_CS_MemAbsGet_Get_BsConst_PCB_Temperature_Sensor_Conv_SafeCopy2: operation=rp_CS_MemAbsGet.Get_BsConst_PCB_Temperature_Sensor_Conv_SafeCopy2
          OA_rp_CS_MemAbsGet_Get_BsConst_Display_Illum_Max_Level_SafeCopy2: operation=rp_CS_MemAbsGet.Get_BsConst_Display_Illum_Max_Level_SafeCopy2
          OA_rp_CS_MemAbsGet_Get_BsConst_PWM_boost_bypass_duty_SafeCopy2: operation=rp_CS_MemAbsGet.Get_BsConst_PWM_boost_bypass_duty_SafeCopy2
          OA_rp_CS_MemAbsGet_Get_BsConst_BsConst_Illumination_ReservedByte_SafeCopy2: operation=rp_CS_MemAbsGet.Get_BsConst_BsConst_Illumination_ReservedByte_SafeCopy2
          OA_rp_CS_MemAbsGet_Get_BsConst_Audio_Element: operation=rp_CS_MemAbsGet.Get_BsConst_Audio_Element
          OA_rp_CS_MemAbsGet_Get_BsConst_Warning_Element: operation=rp_CS_MemAbsGet.Get_BsConst_Warning_Element
          OA_rp_CS_MemAbsGet_Get_BsConst_RealTimeClock_Element: operation=rp_CS_MemAbsGet.Get_BsConst_RealTimeClock_Element
          OA_rp_CS_MemAbsGet_Get_BsConst_Communication_Element: operation=rp_CS_MemAbsGet.Get_BsConst_Communication_Element
          OA_rp_CS_MemAbsGet_Get_BsConst_Power_Element: operation=rp_CS_MemAbsGet.Get_BsConst_Power_Element
          OA_rp_CS_MemAbsGet_Get_BsConst_ServiceReminder_Element: operation=rp_CS_MemAbsGet.Get_BsConst_ServiceReminder_Element
          OA_rp_CS_MemAbsGet_Get_BsConst_EngOffTimer_Element: operation=rp_CS_MemAbsGet.Get_BsConst_EngOffTimer_Element
          OA_rp_CS_MemAbsGet_Get_BsCys_Certicificate_Element: operation=rp_CS_MemAbsGet.Get_BsCys_Certicificate_Element
          OA_rp_CS_MemAbsGet_Get_RefCys_Certicificate_Element: operation=rp_CS_MemAbsGet.Get_RefCys_Certicificate_Element
          OA_rp_CS_MemAbsGet_Get_RefCys_Certicificate1_Element: operation=rp_CS_MemAbsGet.Get_RefCys_Certicificate1_Element
          OA_rp_CS_MemAbsGet_Get_BsRt_Odometer_Element: operation=rp_CS_MemAbsGet.Get_BsRt_Odometer_Element
          OA_rp_CS_MemAbsGet_Get_BsRt_SpeedoGauge_Element: operation=rp_CS_MemAbsGet.Get_BsRt_SpeedoGauge_Element
          OA_rp_CS_MemAbsGet_Get_BsRt_TachoGauge_Element: operation=rp_CS_MemAbsGet.Get_BsRt_TachoGauge_Element
          OA_rp_CS_MemAbsGet_Get_BsRt_FuelGauge_Element: operation=rp_CS_MemAbsGet.Get_BsRt_FuelGauge_Element
          OA_rp_CS_MemAbsGet_Get_BsRt_TempGauge_Element: operation=rp_CS_MemAbsGet.Get_BsRt_TempGauge_Element
          OA_rp_CS_MemAbsGet_Get_BsRt_PowerGauge_Element: operation=rp_CS_MemAbsGet.Get_BsRt_PowerGauge_Element
          OA_rp_CS_MemAbsGet_Get_BsRt_OilGauge_Element: operation=rp_CS_MemAbsGet.Get_BsRt_OilGauge_Element
          OA_rp_CS_MemAbsGet_Get_BsRt_TripComputer_Element: operation=rp_CS_MemAbsGet.Get_BsRt_TripComputer_Element
          OA_rp_CS_MemAbsGet_Get_BsRt_Warning_Element: operation=rp_CS_MemAbsGet.Get_BsRt_Warning_Element
          OA_rp_CS_MemAbsGet_Get_BsRt_RealTimeClock_Element: operation=rp_CS_MemAbsGet.Get_BsRt_RealTimeClock_Element
          OA_rp_CS_MemAbsGet_Get_BsRt_Personalization_Element: operation=rp_CS_MemAbsGet.Get_BsRt_Personalization_Element
          OA_rp_CS_MemAbsGet_Get_BsRt_Illumination_Element: operation=rp_CS_MemAbsGet.Get_BsRt_Illumination_Element
          OA_rp_CS_MemAbsGet_Get_BsRt_CusDlt_Element: operation=rp_CS_MemAbsGet.Get_BsRt_CusDlt_Element
          OA_rp_CS_MemAbsGet_Get_BsReten_Odometer_Element: operation=rp_CS_MemAbsGet.Get_BsReten_Odometer_Element
          OA_rp_CS_MemAbsGet_Get_BsReten_Gauges_Element: operation=rp_CS_MemAbsGet.Get_BsReten_Gauges_Element
          OA_rp_CS_MemAbsGet_Get_BsReten_Tripcomputer_Element: operation=rp_CS_MemAbsGet.Get_BsReten_Tripcomputer_Element
          OA_rp_CS_MemAbsGet_Get_BsReten_Illumination_Element: operation=rp_CS_MemAbsGet.Get_BsReten_Illumination_Element
          OA_rp_CS_MemAbsGet_Get_BsReten_Audio_Element: operation=rp_CS_MemAbsGet.Get_BsReten_Audio_Element
          OA_rp_CS_MemAbsGet_Get_BsReten_Warning_Element: operation=rp_CS_MemAbsGet.Get_BsReten_Warning_Element
          OA_rp_CS_MemAbsGet_Get_BsReten_RealTimeClock_Element: operation=rp_CS_MemAbsGet.Get_BsReten_RealTimeClock_Element
          OA_rp_CS_MemAbsGet_Get_BsReten_Communication_Element: operation=rp_CS_MemAbsGet.Get_BsReten_Communication_Element
          OA_rp_CS_MemAbsGet_Get_BsReten_Personalization_Element: operation=rp_CS_MemAbsGet.Get_BsReten_Personalization_Element
          OA_rp_CS_MemAbsGet_Get_BsReten_Power_Element: operation=rp_CS_MemAbsGet.Get_BsReten_Power_Element
          OA_rp_CS_MemAbsGet_Get_BsReten_Display_Element: operation=rp_CS_MemAbsGet.Get_BsReten_Display_Element
          OA_rp_CS_MemAbsGet_Get_BsDiag_ErrorRecord_Element: operation=rp_CS_MemAbsGet.Get_BsDiag_ErrorRecord_Element
          OA_rp_CS_MemAbsGet_Get_BsDiag_Dtc_Element: operation=rp_CS_MemAbsGet.Get_BsDiag_Dtc_Element
          OA_rp_GetNVM_IlluminationElement_Get_BsShare_SwUpdReflash_Element: operation=rp_GetNVM_IlluminationElement.Get_BsShare_SwUpdReflash_Element
          OA_rp_GetNVM_IlluminationElement_Get_BsShare_SwUpdFotaMode_Element: operation=rp_GetNVM_IlluminationElement.Get_BsShare_SwUpdFotaMode_Element
          OA_rp_GetNVM_IlluminationElement_Get_BsShare_SwUpdFotaFinPrint_Element: operation=rp_GetNVM_IlluminationElement.Get_BsShare_SwUpdFotaFinPrint_Element
          OA_rp_GetNVM_IlluminationElement_Get_BsShare_SwUpdFotaStatus_Element: operation=rp_GetNVM_IlluminationElement.Get_BsShare_SwUpdFotaStatus_Element
          OA_rp_GetNVM_IlluminationElement_Get_BsShare_SwUpdFotadecrypt_Element: operation=rp_GetNVM_IlluminationElement.Get_BsShare_SwUpdFotadecrypt_Element
          OA_rp_GetNVM_IlluminationElement_Get_BsShare_EcuPartNumber_Element: operation=rp_GetNVM_IlluminationElement.Get_BsShare_EcuPartNumber_Element
          OA_rp_GetNVM_IlluminationElement_Get_BsShare_VisteonPartNumber: operation=rp_GetNVM_IlluminationElement.Get_BsShare_VisteonPartNumber
          OA_rp_GetNVM_IlluminationElement_Get_BsShare_VisteonPCBPartNumber: operation=rp_GetNVM_IlluminationElement.Get_BsShare_VisteonPCBPartNumber
          OA_rp_GetNVM_IlluminationElement_Get_BsShare_ProductSerialNumber: operation=rp_GetNVM_IlluminationElement.Get_BsShare_ProductSerialNumber
          OA_rp_GetNVM_IlluminationElement_Get_BsShare_PCBSerialNumber: operation=rp_GetNVM_IlluminationElement.Get_BsShare_PCBSerialNumber
          OA_rp_GetNVM_IlluminationElement_Get_BsShare_SMTManufacturingDate: operation=rp_GetNVM_IlluminationElement.Get_BsShare_SMTManufacturingDate
          OA_rp_GetNVM_IlluminationElement_Get_BsShare_AssemblyManufacturingDate: operation=rp_GetNVM_IlluminationElement.Get_BsShare_AssemblyManufacturingDate
          OA_rp_GetNVM_IlluminationElement_Get_BsShare_SMTPlantNumber: operation=rp_GetNVM_IlluminationElement.Get_BsShare_SMTPlantNumber
          OA_rp_GetNVM_IlluminationElement_Get_BsShare_AssemblyPlantNumber: operation=rp_GetNVM_IlluminationElement.Get_BsShare_AssemblyPlantNumber
          OA_rp_GetNVM_IlluminationElement_Get_BsShare_HWModification: operation=rp_GetNVM_IlluminationElement.Get_BsShare_HWModification
          OA_rp_GetNVM_IlluminationElement_Get_BsShare_VisMeet_Element: operation=rp_GetNVM_IlluminationElement.Get_BsShare_VisMeet_Element
          OA_rp_GetNVM_IlluminationElement_Get_BsShare_VisMeet_EOLEntry_Element: operation=rp_GetNVM_IlluminationElement.Get_BsShare_VisMeet_EOLEntry_Element
          OA_rp_GetNVM_IlluminationElement_Get_BsShare_VehicleConfig_Element: operation=rp_GetNVM_IlluminationElement.Get_BsShare_VehicleConfig_Element
          OA_rp_GetNVM_IlluminationElement_Get_BsConst_SpeedoGauge_Element: operation=rp_GetNVM_IlluminationElement.Get_BsConst_SpeedoGauge_Element
          OA_rp_GetNVM_IlluminationElement_Get_BsConst_TachoGauge_Element: operation=rp_GetNVM_IlluminationElement.Get_BsConst_TachoGauge_Element
          OA_rp_GetNVM_IlluminationElement_Get_BsConst_FuelGauge_Element: operation=rp_GetNVM_IlluminationElement.Get_BsConst_FuelGauge_Element
          OA_rp_GetNVM_IlluminationElement_Get_BsConst_TempGauge_Element: operation=rp_GetNVM_IlluminationElement.Get_BsConst_TempGauge_Element
          OA_rp_GetNVM_IlluminationElement_Get_BsConst_PowerGauge_Element: operation=rp_GetNVM_IlluminationElement.Get_BsConst_PowerGauge_Element
          OA_rp_GetNVM_IlluminationElement_Get_BsConst_OilGauge_Element: operation=rp_GetNVM_IlluminationElement.Get_BsConst_OilGauge_Element
          OA_rp_GetNVM_IlluminationElement_Get_BsConst_TripComputer_Element: operation=rp_GetNVM_IlluminationElement.Get_BsConst_TripComputer_Element
          OA_rp_GetNVM_IlluminationElement_Get_BsConst_Compensation_Line_Slope_m: operation=rp_GetNVM_IlluminationElement.Get_BsConst_Compensation_Line_Slope_m
          OA_rp_GetNVM_IlluminationElement_Get_BsConst_Compensation_Line_Shift_b: operation=rp_GetNVM_IlluminationElement.Get_BsConst_Compensation_Line_Shift_b
          OA_rp_GetNVM_IlluminationElement_Get_BsConst_Lookup_Curve_HotSpot_Coef_X: operation=rp_GetNVM_IlluminationElement.Get_BsConst_Lookup_Curve_HotSpot_Coef_X
          OA_rp_GetNVM_IlluminationElement_Get_BsConst_Lookup_Curve_HotSpot_Coef_Y: operation=rp_GetNVM_IlluminationElement.Get_BsConst_Lookup_Curve_HotSpot_Coef_Y
          OA_rp_GetNVM_IlluminationElement_Get_BsConst_Temp_Threshold_Hysteresis_Derating: operation=rp_GetNVM_IlluminationElement.Get_BsConst_Temp_Threshold_Hysteresis_Derating
          OA_rp_GetNVM_IlluminationElement_Get_BsConst_Derating_Backlight_Disable: operation=rp_GetNVM_IlluminationElement.Get_BsConst_Derating_Backlight_Disable
          OA_rp_GetNVM_IlluminationElement_Get_BsConst_Temperature_Sensor_Conv: operation=rp_GetNVM_IlluminationElement.Get_BsConst_Temperature_Sensor_Conv
          OA_rp_GetNVM_IlluminationElement_Get_BsConst_PCB_Temperature_Sensor_Conv: operation=rp_GetNVM_IlluminationElement.Get_BsConst_PCB_Temperature_Sensor_Conv
          OA_rp_GetNVM_IlluminationElement_Get_BsConst_Display_Illum_Max_Level: operation=rp_GetNVM_IlluminationElement.Get_BsConst_Display_Illum_Max_Level
          OA_rp_GetNVM_IlluminationElement_Get_BsConst_PWM_boost_bypass_duty: operation=rp_GetNVM_IlluminationElement.Get_BsConst_PWM_boost_bypass_duty
          OA_rp_GetNVM_IlluminationElement_Get_BsConst_BsConst_Illumination_ReservedByte: operation=rp_GetNVM_IlluminationElement.Get_BsConst_BsConst_Illumination_ReservedByte
          OA_rp_GetNVM_IlluminationElement_Get_BsConst_Compensation_Line_Slope_m_SafeCopy1: operation=rp_GetNVM_IlluminationElement.Get_BsConst_Compensation_Line_Slope_m_SafeCopy1
          OA_rp_GetNVM_IlluminationElement_Get_BsConst_Compensation_Line_Shift_b_SafeCopy1: operation=rp_GetNVM_IlluminationElement.Get_BsConst_Compensation_Line_Shift_b_SafeCopy1
          OA_rp_GetNVM_IlluminationElement_Get_BsConst_Lookup_Curve_HotSpot_Coef_X_SafeCopy1: operation=rp_GetNVM_IlluminationElement.Get_BsConst_Lookup_Curve_HotSpot_Coef_X_SafeCopy1
          OA_rp_GetNVM_IlluminationElement_Get_BsConst_Lookup_Curve_HotSpot_Coef_Y_SafeCopy1: operation=rp_GetNVM_IlluminationElement.Get_BsConst_Lookup_Curve_HotSpot_Coef_Y_SafeCopy1
          OA_rp_GetNVM_IlluminationElement_Get_BsConst_Temp_Threshold_Hysteresis_Derating_SafeCopy1: operation=rp_GetNVM_IlluminationElement.Get_BsConst_Temp_Threshold_Hysteresis_Derating_SafeCopy1
          OA_rp_GetNVM_IlluminationElement_Get_BsConst_Derating_Backlight_Disable_SafeCopy1: operation=rp_GetNVM_IlluminationElement.Get_BsConst_Derating_Backlight_Disable_SafeCopy1
          OA_rp_GetNVM_IlluminationElement_Get_BsConst_Temperature_Sensor_Conv_SafeCopy1: operation=rp_GetNVM_IlluminationElement.Get_BsConst_Temperature_Sensor_Conv_SafeCopy1
          OA_rp_GetNVM_IlluminationElement_Get_BsConst_PCB_Temperature_Sensor_Conv_SafeCopy1: operation=rp_GetNVM_IlluminationElement.Get_BsConst_PCB_Temperature_Sensor_Conv_SafeCopy1
          OA_rp_GetNVM_IlluminationElement_Get_BsConst_Display_Illum_Max_Level_SafeCopy1: operation=rp_GetNVM_IlluminationElement.Get_BsConst_Display_Illum_Max_Level_SafeCopy1
          OA_rp_GetNVM_IlluminationElement_Get_BsConst_PWM_boost_bypass_duty_SafeCopy1: operation=rp_GetNVM_IlluminationElement.Get_BsConst_PWM_boost_bypass_duty_SafeCopy1
          OA_rp_GetNVM_IlluminationElement_Get_BsConst_BsConst_Illumination_ReservedByte_SafeCopy1: operation=rp_GetNVM_IlluminationElement.Get_BsConst_BsConst_Illumination_ReservedByte_SafeCopy1
          OA_rp_GetNVM_IlluminationElement_Get_BsConst_Compensation_Line_Slope_m_SafeCopy2: operation=rp_GetNVM_IlluminationElement.Get_BsConst_Compensation_Line_Slope_m_SafeCopy2
          OA_rp_GetNVM_IlluminationElement_Get_BsConst_Compensation_Line_Shift_b_SafeCopy2: operation=rp_GetNVM_IlluminationElement.Get_BsConst_Compensation_Line_Shift_b_SafeCopy2
          OA_rp_GetNVM_IlluminationElement_Get_BsConst_Lookup_Curve_HotSpot_Coef_X_SafeCopy2: operation=rp_GetNVM_IlluminationElement.Get_BsConst_Lookup_Curve_HotSpot_Coef_X_SafeCopy2
          OA_rp_GetNVM_IlluminationElement_Get_BsConst_Lookup_Curve_HotSpot_Coef_Y_SafeCopy2: operation=rp_GetNVM_IlluminationElement.Get_BsConst_Lookup_Curve_HotSpot_Coef_Y_SafeCopy2
          OA_rp_GetNVM_IlluminationElement_Get_BsConst_Temp_Threshold_Hysteresis_Derating_SafeCopy2: operation=rp_GetNVM_IlluminationElement.Get_BsConst_Temp_Threshold_Hysteresis_Derating_SafeCopy2
          OA_rp_GetNVM_IlluminationElement_Get_BsConst_Derating_Backlight_Disable_SafeCopy2: operation=rp_GetNVM_IlluminationElement.Get_BsConst_Derating_Backlight_Disable_SafeCopy2
          OA_rp_GetNVM_IlluminationElement_Get_BsConst_Temperature_Sensor_Conv_SafeCopy2: operation=rp_GetNVM_IlluminationElement.Get_BsConst_Temperature_Sensor_Conv_SafeCopy2
          OA_rp_GetNVM_IlluminationElement_Get_BsConst_PCB_Temperature_Sensor_Conv_SafeCopy2: operation=rp_GetNVM_IlluminationElement.Get_BsConst_PCB_Temperature_Sensor_Conv_SafeCopy2
          OA_rp_GetNVM_IlluminationElement_Get_BsConst_Display_Illum_Max_Level_SafeCopy2: operation=rp_GetNVM_IlluminationElement.Get_BsConst_Display_Illum_Max_Level_SafeCopy2
          OA_rp_GetNVM_IlluminationElement_Get_BsConst_PWM_boost_bypass_duty_SafeCopy2: operation=rp_GetNVM_IlluminationElement.Get_BsConst_PWM_boost_bypass_duty_SafeCopy2
          OA_rp_GetNVM_IlluminationElement_Get_BsConst_BsConst_Illumination_ReservedByte_SafeCopy2: operation=rp_GetNVM_IlluminationElement.Get_BsConst_BsConst_Illumination_ReservedByte_SafeCopy2
          OA_rp_GetNVM_IlluminationElement_Get_BsConst_Audio_Element: operation=rp_GetNVM_IlluminationElement.Get_BsConst_Audio_Element
          OA_rp_GetNVM_IlluminationElement_Get_BsConst_Warning_Element: operation=rp_GetNVM_IlluminationElement.Get_BsConst_Warning_Element
          OA_rp_GetNVM_IlluminationElement_Get_BsConst_RealTimeClock_Element: operation=rp_GetNVM_IlluminationElement.Get_BsConst_RealTimeClock_Element
          OA_rp_GetNVM_IlluminationElement_Get_BsConst_Communication_Element: operation=rp_GetNVM_IlluminationElement.Get_BsConst_Communication_Element
          OA_rp_GetNVM_IlluminationElement_Get_BsConst_Power_Element: operation=rp_GetNVM_IlluminationElement.Get_BsConst_Power_Element
          OA_rp_GetNVM_IlluminationElement_Get_BsConst_ServiceReminder_Element: operation=rp_GetNVM_IlluminationElement.Get_BsConst_ServiceReminder_Element
          OA_rp_GetNVM_IlluminationElement_Get_BsConst_EngOffTimer_Element: operation=rp_GetNVM_IlluminationElement.Get_BsConst_EngOffTimer_Element
          OA_rp_GetNVM_IlluminationElement_Get_BsCys_Certicificate_Element: operation=rp_GetNVM_IlluminationElement.Get_BsCys_Certicificate_Element
          OA_rp_GetNVM_IlluminationElement_Get_RefCys_Certicificate_Element: operation=rp_GetNVM_IlluminationElement.Get_RefCys_Certicificate_Element
          OA_rp_GetNVM_IlluminationElement_Get_RefCys_Certicificate1_Element: operation=rp_GetNVM_IlluminationElement.Get_RefCys_Certicificate1_Element
          OA_rp_GetNVM_IlluminationElement_Get_BsRt_Odometer_Element: operation=rp_GetNVM_IlluminationElement.Get_BsRt_Odometer_Element
          OA_rp_GetNVM_IlluminationElement_Get_BsRt_SpeedoGauge_Element: operation=rp_GetNVM_IlluminationElement.Get_BsRt_SpeedoGauge_Element
          OA_rp_GetNVM_IlluminationElement_Get_BsRt_TachoGauge_Element: operation=rp_GetNVM_IlluminationElement.Get_BsRt_TachoGauge_Element
          OA_rp_GetNVM_IlluminationElement_Get_BsRt_FuelGauge_Element: operation=rp_GetNVM_IlluminationElement.Get_BsRt_FuelGauge_Element
          OA_rp_GetNVM_IlluminationElement_Get_BsRt_TempGauge_Element: operation=rp_GetNVM_IlluminationElement.Get_BsRt_TempGauge_Element
          OA_rp_GetNVM_IlluminationElement_Get_BsRt_PowerGauge_Element: operation=rp_GetNVM_IlluminationElement.Get_BsRt_PowerGauge_Element
          OA_rp_GetNVM_IlluminationElement_Get_BsRt_OilGauge_Element: operation=rp_GetNVM_IlluminationElement.Get_BsRt_OilGauge_Element
          OA_rp_GetNVM_IlluminationElement_Get_BsRt_TripComputer_Element: operation=rp_GetNVM_IlluminationElement.Get_BsRt_TripComputer_Element
          OA_rp_GetNVM_IlluminationElement_Get_BsRt_Warning_Element: operation=rp_GetNVM_IlluminationElement.Get_BsRt_Warning_Element
          OA_rp_GetNVM_IlluminationElement_Get_BsRt_RealTimeClock_Element: operation=rp_GetNVM_IlluminationElement.Get_BsRt_RealTimeClock_Element
          OA_rp_GetNVM_IlluminationElement_Get_BsRt_Personalization_Element: operation=rp_GetNVM_IlluminationElement.Get_BsRt_Personalization_Element
          OA_rp_GetNVM_IlluminationElement_Get_BsRt_Illumination_Element: operation=rp_GetNVM_IlluminationElement.Get_BsRt_Illumination_Element
          OA_rp_GetNVM_IlluminationElement_Get_BsRt_CusDlt_Element: operation=rp_GetNVM_IlluminationElement.Get_BsRt_CusDlt_Element
          OA_rp_GetNVM_IlluminationElement_Get_BsReten_Odometer_Element: operation=rp_GetNVM_IlluminationElement.Get_BsReten_Odometer_Element
          OA_rp_GetNVM_IlluminationElement_Get_BsReten_Gauges_Element: operation=rp_GetNVM_IlluminationElement.Get_BsReten_Gauges_Element
          OA_rp_GetNVM_IlluminationElement_Get_BsReten_Tripcomputer_Element: operation=rp_GetNVM_IlluminationElement.Get_BsReten_Tripcomputer_Element
          OA_rp_GetNVM_IlluminationElement_Get_BsReten_Illumination_Element: operation=rp_GetNVM_IlluminationElement.Get_BsReten_Illumination_Element
          OA_rp_GetNVM_IlluminationElement_Get_BsReten_Audio_Element: operation=rp_GetNVM_IlluminationElement.Get_BsReten_Audio_Element
          OA_rp_GetNVM_IlluminationElement_Get_BsReten_Warning_Element: operation=rp_GetNVM_IlluminationElement.Get_BsReten_Warning_Element
          OA_rp_GetNVM_IlluminationElement_Get_BsReten_RealTimeClock_Element: operation=rp_GetNVM_IlluminationElement.Get_BsReten_RealTimeClock_Element
          OA_rp_GetNVM_IlluminationElement_Get_BsReten_Communication_Element: operation=rp_GetNVM_IlluminationElement.Get_BsReten_Communication_Element
          OA_rp_GetNVM_IlluminationElement_Get_BsReten_Personalization_Element: operation=rp_GetNVM_IlluminationElement.Get_BsReten_Personalization_Element
          OA_rp_GetNVM_IlluminationElement_Get_BsReten_Power_Element: operation=rp_GetNVM_IlluminationElement.Get_BsReten_Power_Element
          OA_rp_GetNVM_IlluminationElement_Get_BsReten_Display_Element: operation=rp_GetNVM_IlluminationElement.Get_BsReten_Display_Element
          OA_rp_GetNVM_IlluminationElement_Get_BsDiag_ErrorRecord_Element: operation=rp_GetNVM_IlluminationElement.Get_BsDiag_ErrorRecord_Element
          OA_rp_GetNVM_IlluminationElement_Get_BsDiag_Dtc_Element: operation=rp_GetNVM_IlluminationElement.Get_BsDiag_Dtc_Element
          OA_rp_PwmSetDuty_PwmSetDuty: operation=rp_PwmSetDuty.PwmSetDuty
          OA_rp_PwmSetDuty_PwmSetDutyAndPeriod: operation=rp_PwmSetDuty.PwmSetDutyAndPeriod
          OA_rp_PwmSetDuty_PwmSetIdeal: operation=rp_PwmSetDuty.PwmSetIdeal
          OA_rp_SetNVM_IlluminationElement_Set_BsShare_SwUpdReflash_Element: operation=rp_SetNVM_IlluminationElement.Set_BsShare_SwUpdReflash_Element
          OA_rp_SetNVM_IlluminationElement_Set_BsShare_SwUpdFotaMode_Element: operation=rp_SetNVM_IlluminationElement.Set_BsShare_SwUpdFotaMode_Element
          OA_rp_SetNVM_IlluminationElement_Set_BsShare_SwUpdFotaFinPrint_Element: operation=rp_SetNVM_IlluminationElement.Set_BsShare_SwUpdFotaFinPrint_Element
          OA_rp_SetNVM_IlluminationElement_Set_BsShare_SwUpdFotaStatus_Element: operation=rp_SetNVM_IlluminationElement.Set_BsShare_SwUpdFotaStatus_Element
          OA_rp_SetNVM_IlluminationElement_Set_BsShare_SwUpdFotadecrypt_Element: operation=rp_SetNVM_IlluminationElement.Set_BsShare_SwUpdFotadecrypt_Element
          OA_rp_SetNVM_IlluminationElement_Set_BsShare_EcuPartNumber_Element: operation=rp_SetNVM_IlluminationElement.Set_BsShare_EcuPartNumber_Element
          OA_rp_SetNVM_IlluminationElement_Set_BsShare_VisteonPartNumber: operation=rp_SetNVM_IlluminationElement.Set_BsShare_VisteonPartNumber
          OA_rp_SetNVM_IlluminationElement_Set_BsShare_VisteonPCBPartNumber: operation=rp_SetNVM_IlluminationElement.Set_BsShare_VisteonPCBPartNumber
          OA_rp_SetNVM_IlluminationElement_Set_BsShare_ProductSerialNumber: operation=rp_SetNVM_IlluminationElement.Set_BsShare_ProductSerialNumber
          OA_rp_SetNVM_IlluminationElement_Set_BsShare_PCBSerialNumber: operation=rp_SetNVM_IlluminationElement.Set_BsShare_PCBSerialNumber
          OA_rp_SetNVM_IlluminationElement_Set_BsShare_SMTManufacturingDate: operation=rp_SetNVM_IlluminationElement.Set_BsShare_SMTManufacturingDate
          OA_rp_SetNVM_IlluminationElement_Set_BsShare_AssemblyManufacturingDate: operation=rp_SetNVM_IlluminationElement.Set_BsShare_AssemblyManufacturingDate
          OA_rp_SetNVM_IlluminationElement_Set_BsShare_SMTPlantNumber: operation=rp_SetNVM_IlluminationElement.Set_BsShare_SMTPlantNumber
          OA_rp_SetNVM_IlluminationElement_Set_BsShare_AssemblyPlantNumber: operation=rp_SetNVM_IlluminationElement.Set_BsShare_AssemblyPlantNumber
          OA_rp_SetNVM_IlluminationElement_Set_BsShare_HWModification: operation=rp_SetNVM_IlluminationElement.Set_BsShare_HWModification
          OA_rp_SetNVM_IlluminationElement_Set_BsShare_VisMeet_Element: operation=rp_SetNVM_IlluminationElement.Set_BsShare_VisMeet_Element
          OA_rp_SetNVM_IlluminationElement_Set_BsShare_VisMeet_EOLEntry_Element: operation=rp_SetNVM_IlluminationElement.Set_BsShare_VisMeet_EOLEntry_Element
          OA_rp_SetNVM_IlluminationElement_Set_BsShare_VehicleConfig_Element: operation=rp_SetNVM_IlluminationElement.Set_BsShare_VehicleConfig_Element
          OA_rp_SetNVM_IlluminationElement_Set_BsConst_SpeedoGauge_Element: operation=rp_SetNVM_IlluminationElement.Set_BsConst_SpeedoGauge_Element
          OA_rp_SetNVM_IlluminationElement_Set_BsConst_TachoGauge_Element: operation=rp_SetNVM_IlluminationElement.Set_BsConst_TachoGauge_Element
          OA_rp_SetNVM_IlluminationElement_Set_BsConst_FuelGauge_Element: operation=rp_SetNVM_IlluminationElement.Set_BsConst_FuelGauge_Element
          OA_rp_SetNVM_IlluminationElement_Set_BsConst_TempGauge_Element: operation=rp_SetNVM_IlluminationElement.Set_BsConst_TempGauge_Element
          OA_rp_SetNVM_IlluminationElement_Set_BsConst_PowerGauge_Element: operation=rp_SetNVM_IlluminationElement.Set_BsConst_PowerGauge_Element
          OA_rp_SetNVM_IlluminationElement_Set_BsConst_OilGauge_Element: operation=rp_SetNVM_IlluminationElement.Set_BsConst_OilGauge_Element
          OA_rp_SetNVM_IlluminationElement_Set_BsConst_TripComputer_Element: operation=rp_SetNVM_IlluminationElement.Set_BsConst_TripComputer_Element
          OA_rp_SetNVM_IlluminationElement_Set_BsConst_Compensation_Line_Slope_m: operation=rp_SetNVM_IlluminationElement.Set_BsConst_Compensation_Line_Slope_m
          OA_rp_SetNVM_IlluminationElement_Set_BsConst_Compensation_Line_Shift_b: operation=rp_SetNVM_IlluminationElement.Set_BsConst_Compensation_Line_Shift_b
          OA_rp_SetNVM_IlluminationElement_Set_BsConst_Lookup_Curve_HotSpot_Coef_X: operation=rp_SetNVM_IlluminationElement.Set_BsConst_Lookup_Curve_HotSpot_Coef_X
          OA_rp_SetNVM_IlluminationElement_Set_BsConst_Lookup_Curve_HotSpot_Coef_Y: operation=rp_SetNVM_IlluminationElement.Set_BsConst_Lookup_Curve_HotSpot_Coef_Y
          OA_rp_SetNVM_IlluminationElement_Set_BsConst_Temp_Threshold_Hysteresis_Derating: operation=rp_SetNVM_IlluminationElement.Set_BsConst_Temp_Threshold_Hysteresis_Derating
          OA_rp_SetNVM_IlluminationElement_Set_BsConst_Derating_Backlight_Disable: operation=rp_SetNVM_IlluminationElement.Set_BsConst_Derating_Backlight_Disable
          OA_rp_SetNVM_IlluminationElement_Set_BsConst_Temperature_Sensor_Conv: operation=rp_SetNVM_IlluminationElement.Set_BsConst_Temperature_Sensor_Conv
          OA_rp_SetNVM_IlluminationElement_Set_BsConst_PCB_Temperature_Sensor_Conv: operation=rp_SetNVM_IlluminationElement.Set_BsConst_PCB_Temperature_Sensor_Conv
          OA_rp_SetNVM_IlluminationElement_Set_BsConst_Display_Illum_Max_Level: operation=rp_SetNVM_IlluminationElement.Set_BsConst_Display_Illum_Max_Level
          OA_rp_SetNVM_IlluminationElement_Set_BsConst_PWM_boost_bypass_duty: operation=rp_SetNVM_IlluminationElement.Set_BsConst_PWM_boost_bypass_duty
          OA_rp_SetNVM_IlluminationElement_Set_BsConst_BsConst_Illumination_ReservedByte: operation=rp_SetNVM_IlluminationElement.Set_BsConst_BsConst_Illumination_ReservedByte
          OA_rp_SetNVM_IlluminationElement_Set_BsConst_Compensation_Line_Slope_m_SafeCopy1: operation=rp_SetNVM_IlluminationElement.Set_BsConst_Compensation_Line_Slope_m_SafeCopy1
          OA_rp_SetNVM_IlluminationElement_Set_BsConst_Compensation_Line_Shift_b_SafeCopy1: operation=rp_SetNVM_IlluminationElement.Set_BsConst_Compensation_Line_Shift_b_SafeCopy1
          OA_rp_SetNVM_IlluminationElement_Set_BsConst_Lookup_Curve_HotSpot_Coef_X_SafeCopy1: operation=rp_SetNVM_IlluminationElement.Set_BsConst_Lookup_Curve_HotSpot_Coef_X_SafeCopy1
          OA_rp_SetNVM_IlluminationElement_Set_BsConst_Lookup_Curve_HotSpot_Coef_Y_SafeCopy1: operation=rp_SetNVM_IlluminationElement.Set_BsConst_Lookup_Curve_HotSpot_Coef_Y_SafeCopy1
          OA_rp_SetNVM_IlluminationElement_Set_BsConst_Temp_Threshold_Hysteresis_Derating_SafeCopy1: operation=rp_SetNVM_IlluminationElement.Set_BsConst_Temp_Threshold_Hysteresis_Derating_SafeCopy1
          OA_rp_SetNVM_IlluminationElement_Set_BsConst_Derating_Backlight_Disable_SafeCopy1: operation=rp_SetNVM_IlluminationElement.Set_BsConst_Derating_Backlight_Disable_SafeCopy1
          OA_rp_SetNVM_IlluminationElement_Set_BsConst_Temperature_Sensor_Conv_SafeCopy1: operation=rp_SetNVM_IlluminationElement.Set_BsConst_Temperature_Sensor_Conv_SafeCopy1
          OA_rp_SetNVM_IlluminationElement_Set_BsConst_PCB_Temperature_Sensor_Conv_SafeCopy1: operation=rp_SetNVM_IlluminationElement.Set_BsConst_PCB_Temperature_Sensor_Conv_SafeCopy1
          OA_rp_SetNVM_IlluminationElement_Set_BsConst_Display_Illum_Max_Level_SafeCopy1: operation=rp_SetNVM_IlluminationElement.Set_BsConst_Display_Illum_Max_Level_SafeCopy1
          OA_rp_SetNVM_IlluminationElement_Set_BsConst_PWM_boost_bypass_duty_SafeCopy1: operation=rp_SetNVM_IlluminationElement.Set_BsConst_PWM_boost_bypass_duty_SafeCopy1
          OA_rp_SetNVM_IlluminationElement_Set_BsConst_BsConst_Illumination_ReservedByte_SafeCopy1: operation=rp_SetNVM_IlluminationElement.Set_BsConst_BsConst_Illumination_ReservedByte_SafeCopy1
          OA_rp_SetNVM_IlluminationElement_Set_BsConst_Compensation_Line_Slope_m_SafeCopy2: operation=rp_SetNVM_IlluminationElement.Set_BsConst_Compensation_Line_Slope_m_SafeCopy2
          OA_rp_SetNVM_IlluminationElement_Set_BsConst_Compensation_Line_Shift_b_SafeCopy2: operation=rp_SetNVM_IlluminationElement.Set_BsConst_Compensation_Line_Shift_b_SafeCopy2
          OA_rp_SetNVM_IlluminationElement_Set_BsConst_Lookup_Curve_HotSpot_Coef_X_SafeCopy2: operation=rp_SetNVM_IlluminationElement.Set_BsConst_Lookup_Curve_HotSpot_Coef_X_SafeCopy2
          OA_rp_SetNVM_IlluminationElement_Set_BsConst_Lookup_Curve_HotSpot_Coef_Y_SafeCopy2: operation=rp_SetNVM_IlluminationElement.Set_BsConst_Lookup_Curve_HotSpot_Coef_Y_SafeCopy2
          OA_rp_SetNVM_IlluminationElement_Set_BsConst_Temp_Threshold_Hysteresis_Derating_SafeCopy2: operation=rp_SetNVM_IlluminationElement.Set_BsConst_Temp_Threshold_Hysteresis_Derating_SafeCopy2
          OA_rp_SetNVM_IlluminationElement_Set_BsConst_Derating_Backlight_Disable_SafeCopy2: operation=rp_SetNVM_IlluminationElement.Set_BsConst_Derating_Backlight_Disable_SafeCopy2
          OA_rp_SetNVM_IlluminationElement_Set_BsConst_Temperature_Sensor_Conv_SafeCopy2: operation=rp_SetNVM_IlluminationElement.Set_BsConst_Temperature_Sensor_Conv_SafeCopy2
          OA_rp_SetNVM_IlluminationElement_Set_BsConst_PCB_Temperature_Sensor_Conv_SafeCopy2: operation=rp_SetNVM_IlluminationElement.Set_BsConst_PCB_Temperature_Sensor_Conv_SafeCopy2
          OA_rp_SetNVM_IlluminationElement_Set_BsConst_Display_Illum_Max_Level_SafeCopy2: operation=rp_SetNVM_IlluminationElement.Set_BsConst_Display_Illum_Max_Level_SafeCopy2
          OA_rp_SetNVM_IlluminationElement_Set_BsConst_PWM_boost_bypass_duty_SafeCopy2: operation=rp_SetNVM_IlluminationElement.Set_BsConst_PWM_boost_bypass_duty_SafeCopy2
          OA_rp_SetNVM_IlluminationElement_Set_BsConst_BsConst_Illumination_ReservedByte_SafeCopy2: operation=rp_SetNVM_IlluminationElement.Set_BsConst_BsConst_Illumination_ReservedByte_SafeCopy2
          OA_rp_SetNVM_IlluminationElement_Set_BsConst_Audio_Element: operation=rp_SetNVM_IlluminationElement.Set_BsConst_Audio_Element
          OA_rp_SetNVM_IlluminationElement_Set_BsConst_Warning_Element: operation=rp_SetNVM_IlluminationElement.Set_BsConst_Warning_Element
          OA_rp_SetNVM_IlluminationElement_Set_BsConst_RealTimeClock_Element: operation=rp_SetNVM_IlluminationElement.Set_BsConst_RealTimeClock_Element
          OA_rp_SetNVM_IlluminationElement_Set_BsConst_Communication_Element: operation=rp_SetNVM_IlluminationElement.Set_BsConst_Communication_Element
          OA_rp_SetNVM_IlluminationElement_Set_BsConst_Power_Element: operation=rp_SetNVM_IlluminationElement.Set_BsConst_Power_Element
          OA_rp_SetNVM_IlluminationElement_Set_BsConst_ServiceReminder_Element: operation=rp_SetNVM_IlluminationElement.Set_BsConst_ServiceReminder_Element
          OA_rp_SetNVM_IlluminationElement_Set_BsConst_EngOffTimer_Element: operation=rp_SetNVM_IlluminationElement.Set_BsConst_EngOffTimer_Element
          OA_rp_SetNVM_IlluminationElement_Set_BsCys_Certicificate_Element: operation=rp_SetNVM_IlluminationElement.Set_BsCys_Certicificate_Element
          OA_rp_SetNVM_IlluminationElement_Set_RefCys_Certicificate_Element: operation=rp_SetNVM_IlluminationElement.Set_RefCys_Certicificate_Element
          OA_rp_SetNVM_IlluminationElement_Set_RefCys_Certicificate1_Element: operation=rp_SetNVM_IlluminationElement.Set_RefCys_Certicificate1_Element
          OA_rp_SetNVM_IlluminationElement_Set_BsRt_Odometer_Element: operation=rp_SetNVM_IlluminationElement.Set_BsRt_Odometer_Element
          OA_rp_SetNVM_IlluminationElement_Set_BsRt_SpeedoGauge_Element: operation=rp_SetNVM_IlluminationElement.Set_BsRt_SpeedoGauge_Element
          OA_rp_SetNVM_IlluminationElement_Set_BsRt_TachoGauge_Element: operation=rp_SetNVM_IlluminationElement.Set_BsRt_TachoGauge_Element
          OA_rp_SetNVM_IlluminationElement_Set_BsRt_FuelGauge_Element: operation=rp_SetNVM_IlluminationElement.Set_BsRt_FuelGauge_Element
          OA_rp_SetNVM_IlluminationElement_Set_BsRt_TempGauge_Element: operation=rp_SetNVM_IlluminationElement.Set_BsRt_TempGauge_Element
          OA_rp_SetNVM_IlluminationElement_Set_BsRt_PowerGauge_Element: operation=rp_SetNVM_IlluminationElement.Set_BsRt_PowerGauge_Element
          OA_rp_SetNVM_IlluminationElement_Set_BsRt_OilGauge_Element: operation=rp_SetNVM_IlluminationElement.Set_BsRt_OilGauge_Element
          OA_rp_SetNVM_IlluminationElement_Set_BsRt_TripComputer_Element: operation=rp_SetNVM_IlluminationElement.Set_BsRt_TripComputer_Element
          OA_rp_SetNVM_IlluminationElement_Set_BsRt_Warning_Element: operation=rp_SetNVM_IlluminationElement.Set_BsRt_Warning_Element
          OA_rp_SetNVM_IlluminationElement_Set_BsRt_RealTimeClock_Element: operation=rp_SetNVM_IlluminationElement.Set_BsRt_RealTimeClock_Element
          OA_rp_SetNVM_IlluminationElement_Set_BsRt_Personalization_Element: operation=rp_SetNVM_IlluminationElement.Set_BsRt_Personalization_Element
          OA_rp_SetNVM_IlluminationElement_Set_BsRt_Illumination_Element: operation=rp_SetNVM_IlluminationElement.Set_BsRt_Illumination_Element
          OA_rp_SetNVM_IlluminationElement_Set_BsRt_CusDlt_Element: operation=rp_SetNVM_IlluminationElement.Set_BsRt_CusDlt_Element
          OA_rp_SetNVM_IlluminationElement_Set_BsReten_Odometer_Element: operation=rp_SetNVM_IlluminationElement.Set_BsReten_Odometer_Element
          OA_rp_SetNVM_IlluminationElement_Set_BsReten_Gauges_Element: operation=rp_SetNVM_IlluminationElement.Set_BsReten_Gauges_Element
          OA_rp_SetNVM_IlluminationElement_Set_BsReten_Tripcomputer_Element: operation=rp_SetNVM_IlluminationElement.Set_BsReten_Tripcomputer_Element
          OA_rp_SetNVM_IlluminationElement_Set_BsReten_Illumination_Element: operation=rp_SetNVM_IlluminationElement.Set_BsReten_Illumination_Element
          OA_rp_SetNVM_IlluminationElement_Set_BsReten_Audio_Element: operation=rp_SetNVM_IlluminationElement.Set_BsReten_Audio_Element
          OA_rp_SetNVM_IlluminationElement_Set_BsReten_Warning_Element: operation=rp_SetNVM_IlluminationElement.Set_BsReten_Warning_Element
          OA_rp_SetNVM_IlluminationElement_Set_BsReten_RealTimeClock_Element: operation=rp_SetNVM_IlluminationElement.Set_BsReten_RealTimeClock_Element
          OA_rp_SetNVM_IlluminationElement_Set_BsReten_Communication_Element: operation=rp_SetNVM_IlluminationElement.Set_BsReten_Communication_Element
          OA_rp_SetNVM_IlluminationElement_Set_BsReten_Personalization_Element: operation=rp_SetNVM_IlluminationElement.Set_BsReten_Personalization_Element
          OA_rp_SetNVM_IlluminationElement_Set_BsReten_Power_Element: operation=rp_SetNVM_IlluminationElement.Set_BsReten_Power_Element
          OA_rp_SetNVM_IlluminationElement_Set_BsReten_Display_Element: operation=rp_SetNVM_IlluminationElement.Set_BsReten_Display_Element
          OA_rp_SetNVM_IlluminationElement_Set_BsDiag_ErrorRecord_Element: operation=rp_SetNVM_IlluminationElement.Set_BsDiag_ErrorRecord_Element
          OA_rp_SetNVM_IlluminationElement_Set_BsDiag_Dtc_Element: operation=rp_SetNVM_IlluminationElement.Set_BsDiag_Dtc_Element
          OA_rp_TmExt_Timer_IsElapsed_Timer_IsElapsed: operation=rp_TmExt_Timer_IsElapsed.Timer_IsElapsed
          OA_rp_TmExt_Timer_IsStarted_Timer_IsStarted: operation=rp_TmExt_Timer_IsStarted.Timer_IsStarted
          OA_rp_TmExt_Timer_Start_Timer_Start: operation=rp_TmExt_Timer_Start.Timer_Start
          OA_rp_TmExt_Timer_Stop_Timer_Stop: operation=rp_TmExt_Timer_Stop.Timer_Stop
          OA_rp_CS_EcuBatteryOutData_EcuBatteryM_GetChannelStatus: operation=rp_CS_EcuBatteryOutData.EcuBatteryM_GetChannelStatus
          OA_rp_CS_EcuBatteryOutData_EcuBatteryM_GetDIOStatus: operation=rp_CS_EcuBatteryOutData.EcuBatteryM_GetDIOStatus
          OA_rp_CS_Backlight_service_SetBrightnessValue: operation=rp_CS_Backlight_service.SetBrightnessValue
          OA_rp_CS_Backlight_service_GetBrightnessValue: operation=rp_CS_Backlight_service.GetBrightnessValue
          OA_rp_CS_Backlight_service_GetThermalValue: operation=rp_CS_Backlight_service.GetThermalValue
      runnable CView_Illumination_Impl_OnCommand: can-be-invoked-concurrently=true
  swc implementation IMPL_View_Illumination: behavior=IB_View_Illumination
